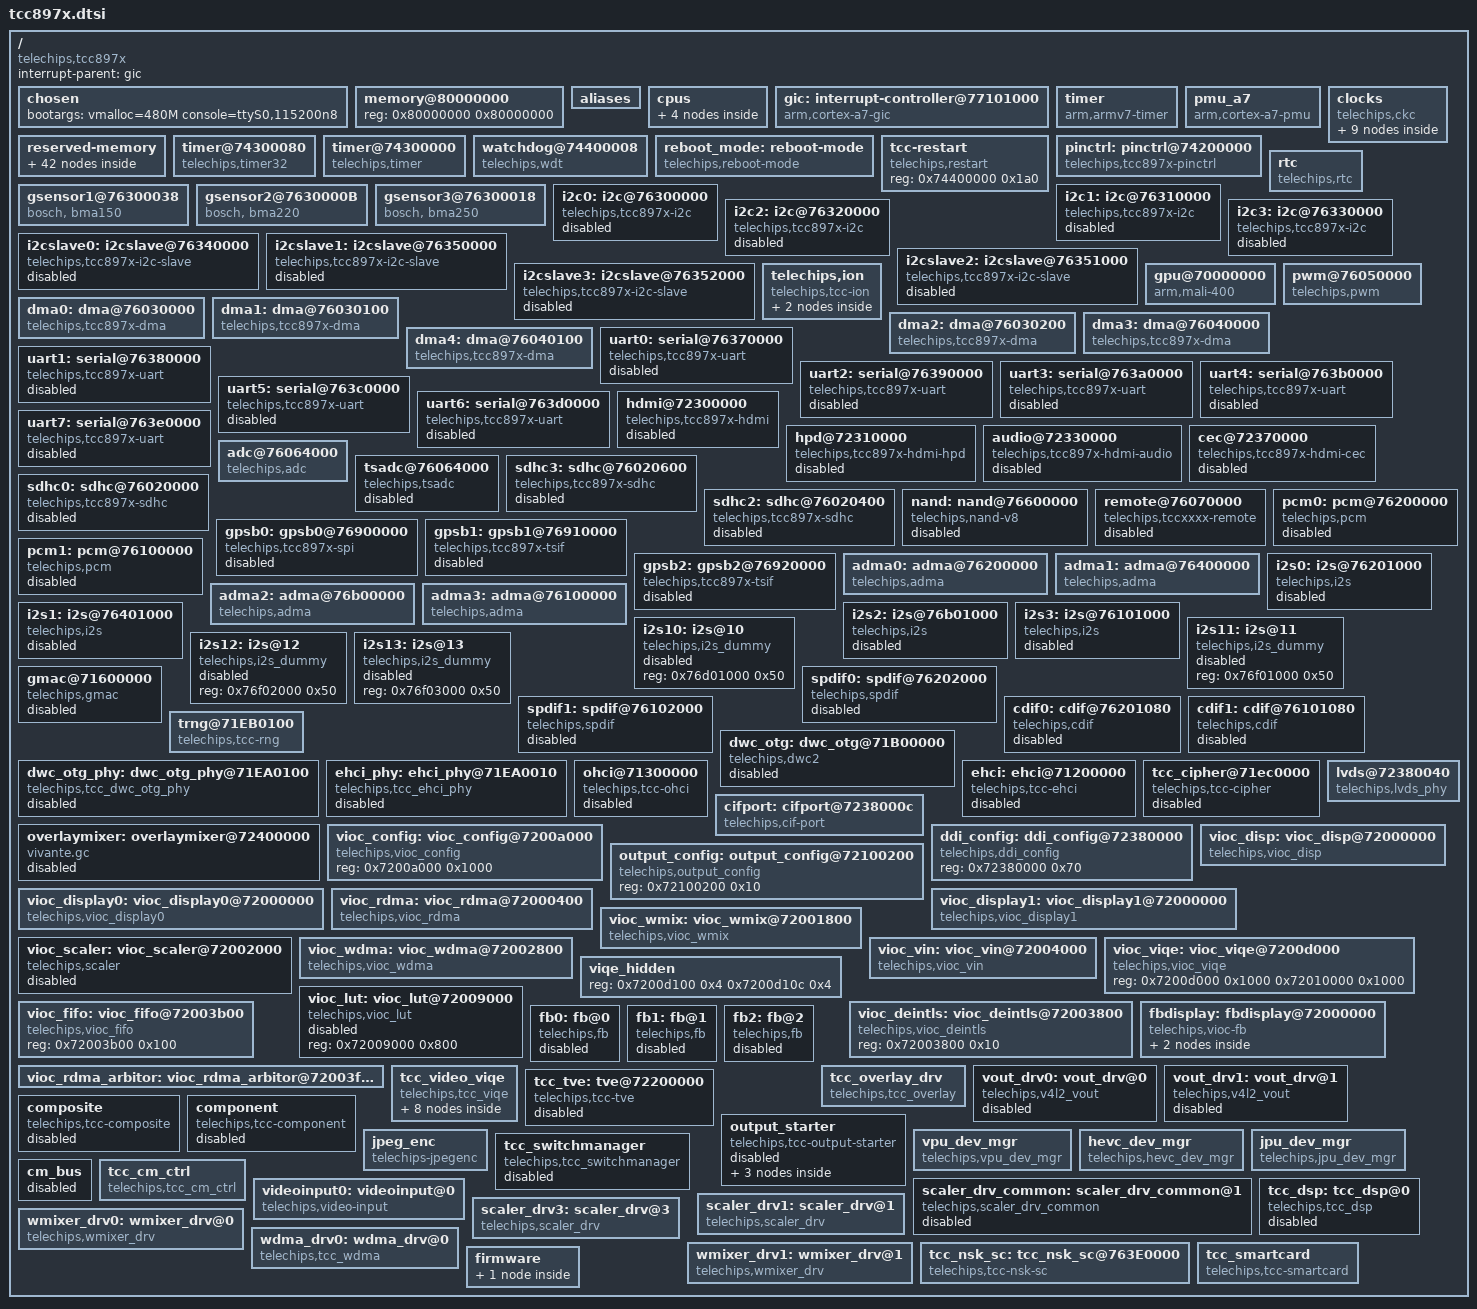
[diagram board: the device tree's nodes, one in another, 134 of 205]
// SPDX-License-Identifier: (GPL-2.0+ OR MIT)
/*
 * Device tree for Telechips TCC897x SoC
 *
 * Copyright (C) 2018 Telechips Inc.
 */

#include <dt-bindings/interrupt-controller/arm-gic.h>
#include <dt-bindings/clock/telechips,tcc897x-clks.h>
#include <dt-bindings/soc/tcc897x-pm.h>
#include <dt-bindings/display/tcc897x-vioc.h>
#include <dt-bindings/power/telechips,boot-mode.h>

#include "tcc-pmap-common.dtsi"

/ {
	compatible = "telechips,tcc897x";
	interrupt-parent = <&gic>;
	#address-cells = <1>;
	#size-cells = <1>;

	chosen {
		bootargs = "vmalloc=480M console=ttyS0,115200n8";
	};

	memory@80000000 {
		#address-cells = <1>;
		#size-cells = <1>;
		device_type = "memory";
		reg = <0x80000000 0x80000000>;
	};

	aliases {
		serial0 = &uart0;
		serial1 = &uart1;
		serial2 = &uart2;
		serial3 = &uart3;
		serial4 = &uart4;
		serial5 = &uart5;
		serial6 = &uart6;
		serial7 = &uart7;
		i2c0 = &i2c0;
		i2c1 = &i2c1;
		i2c2 = &i2c2;
		i2c3 = &i2c3;
		sdhc0 = &sdhc0;
		sdhc2 = &sdhc2;
		sdhc3 = &sdhc3;
		ehci = &ehci;
		pcm0 = &pcm0;
		pcm1 = &pcm1;
		adma0 = &adma0;
		adma1 = &adma1;
		adma2 = &adma2;
		adma3 = &adma3;
		i2s0 = &i2s0;
		i2s1 = &i2s1;
		i2s2 = &i2s2;
		i2s3 = &i2s3;
		i2s10 = &i2s10;
		i2s11 = &i2s11;
		i2s12 = &i2s12;
		i2s13 = &i2s13;
		spdif0 = &spdif0;
		spdif1 = &spdif1;
		cdif0 = &cdif0;
		cdif1 = &cdif1;
		dma0 = &dma0;
		dma1 = &dma1;
		dma2 = &dma2;
		dma3 = &dma3;
		dma4 = &dma4;
		wmixer_drv0 = &wmixer_drv0;
		wmixer_drv1 = &wmixer_drv1;
		scaler_drv1 = &scaler_drv1;
		scaler_drv3 = &scaler_drv3;
		vout_drv0 = &vout_drv0;
		vout_drv1 = &vout_drv1;
		wdma_drv0 = &wdma_drv0;
		videoinput0 = &videoinput0;
		fb0 = &fb0;
		fb1 = &fb1;
		fb2 = &fb2;
	};

	cpus {
		#address-cells = <1>;
		#size-cells = <0>;
		cpu0: cpu@0 {
			device_type = "cpu";
			compatible = "arm,cortex-a7";
			reg = <0x0>;
			clock-frequency = <1000000000>;
			operating-points = <
				/* kHz    uV */
				1000000	1100000
				 925000	1050000
				 850000	1000000
				 775000	 950000
				 700000	 900000
			>;
		};
		cpu1: cpu@1 {
			device_type = "cpu";
			compatible = "arm,cortex-a7";
			reg = <0x1>;
			clock-frequency = <1000000000>;
		};
		cpu2: cpu@2 {
			device_type = "cpu";
			compatible = "arm,cortex-a7";
			reg = <0x2>;
			clock-frequency = <1000000000>;
		};
		cpu3: cpu@3 {
			device_type = "cpu";
			compatible = "arm,cortex-a7";
			reg = <0x3>;
			clock-frequency = <1000000000>;
		};
	};

	gic:interrupt-controller@77101000 {
		compatible = "arm,cortex-a7-gic", "telechips,tcc897x-vpic";
		#interrupt-cells = <3>;
		#address-cells = <0>;
		interrupt-controller;
		reg = <0x77101000 0x1000>,
		      <0x77102000 0x1000>,
		      <0x74100000 0x260>,
		      <0x7460000c 0x8>;
	};

	timer {
		compatible = "arm,armv7-timer";
		interrupts = <GIC_PPI 13 (GIC_CPU_MASK_SIMPLE(4) | IRQ_TYPE_LEVEL_LOW)>,
		             <GIC_PPI 14 (GIC_CPU_MASK_SIMPLE(4) | IRQ_TYPE_LEVEL_LOW)>,
		             <GIC_PPI 11 (GIC_CPU_MASK_SIMPLE(4) | IRQ_TYPE_LEVEL_LOW)>,
		             <GIC_PPI 10 (GIC_CPU_MASK_SIMPLE(4) | IRQ_TYPE_LEVEL_LOW)>;
		always-on;
	};

	pmu_a7 {
		compatible = "arm,cortex-a7-pmu";
		interrupts = <GIC_SPI 64 IRQ_TYPE_LEVEL_LOW>,
		             <GIC_SPI 65 IRQ_TYPE_LEVEL_LOW>,
		             <GIC_SPI 66 IRQ_TYPE_LEVEL_LOW>,
		             <GIC_SPI 67 IRQ_TYPE_LEVEL_LOW>;
	};

	clocks {
		compatible = "telechips,ckc";
		#address-cells = <1>;
		#size-cells = <1>;
		reg = <0x74000000 0x1A8	/* ckc */
		       0x74400000 0x114	/* pmu */
		       0x73810000 0x018	/* memory bus configutaion */
		       0x72380000 0x008	/* display bus configutaion */
		       0x70010000 0x008	/* graphic bus configutaion */
		       0x76066000 0x070	/* io bus configutaion */
		       0x75100000 0x008	/* video bus configutaion */
		       0x71EA0000 0x008	/* hsio bus configutaion */
		       >;
		ranges;

		osc24m: oscillator {
			compatible = "fixed-clock";
			#clock-cells = <0>;
			clock-frequency = <24000000>;
			clock-output-names = "osc24m";
		};

		clk_pll: pll_clk {
			compatible = "telechips,clk-pll";
			#clock-cells = <1>;
			clocks = <&osc24m>;
			clock-output-names = "pll0", "pll1", "pll2", "pll_cb",
					     "pll_mb";
		};

		clk_fbus: clk@74000000 {
			compatible = "telechips,clk-fbus";
			#clock-cells = <1>;
			clock-indices =
				<FBUS_CPU0>, <FBUS_CPU1>, <FBUS_MEM>, <FBUS_DDI>,
				<FBUS_GPU>, <FBUS_IO>, <FBUS_VBUS>, <FBUS_CODA>,
				<FBUS_HSIO>, <FBUS_SMU>, <FBUS_G2D>, <FBUS_CMBUS>,
				<FBUS_HEVC_VCE>, <FBUS_HEVC_VCPU>,
				<FBUS_HEVC_BPU>;
			clock-output-names =
				"fbus_cpu0", "fbus_cpu1", "fbus_mem", "fbus_ddi",
				"fbus_gpu", "fbus_io", "fbus_vbus", "fbus_coda",
				"fbus_hsio", "fbus_smu", "fbus_g2d", "fbus_cmbus",
				"fbus_hevc_vce", "fbus_hevc_vcpu",
				"fbus_hevc_bpu";
			telechips,clock-flags =
				<0>,	/* FBUS_CPU0 */
				<0>,	/* FBUS_CPU1 */
				<(CLK_SET_RATE_GATE | CLK_IGNORE_UNUSED)>,	/* FBUS_MEM */
				<CLK_SET_RATE_GATE>,	/* FBUS_DDI */
				<0>,	/* FBUS_GPU */
				<(CLK_SET_RATE_GATE | CLK_IS_CRITICAL)>,	/* FBUS_IO */
				<CLK_SET_RATE_GATE>,	/* FBUS_VBUS */
				<CLK_SET_RATE_GATE>,	/* FBUS_CODA */
				<CLK_SET_RATE_GATE>,	/* FBUS_HSIO */
				<(CLK_SET_RATE_GATE | CLK_IGNORE_UNUSED)>,	/* FBUS_SMU */
				<CLK_SET_RATE_GATE>,	/* FBUS_G2D */
				<(CLK_SET_RATE_GATE | CLK_IGNORE_UNUSED)>,	/* FBUS_CMBUS */
				<CLK_SET_RATE_GATE>,	/* FBUS_HEVC_VCE */
				<CLK_SET_RATE_GATE>,	/* FBUS_HEVC_VCPU */
				<CLK_SET_RATE_GATE>;	/* FBUS_HEVC_BPU */
		};

		clk_peri: clk@74000080 {
			compatible = "telechips,clk-peri";
			#clock-cells = <1>;
			clock-indices =
				<PERI_TCX>, <PERI_TCT>, <PERI_TCZ>, <PERI_LCD0>,
				<PERI_LCDSI0>, <PERI_LCD1>, <PERI_LCDSI1>,
				<PERI_LCDTIMER>, <PERI_USB_OTG>,
				<PERI_GMAC_PTP>, <PERI_GMAC>, <PERI_USB_OTG_ADP>,
				<PERI_IOB_CEC>, <PERI_OUT0>, <PERI_HDMI>,
				<PERI_HDMIA>, <PERI_OUT1>, <PERI_REMOTE>,
				<PERI_SDMMC0>, <PERI_SDMMC1>, <PERI_SDMMC2>,
				<PERI_SDMMC3>, <PERI_ADAI3>, <PERI_ADAM3>,
				<PERI_SPDIF3>, <PERI_ADAI0>, <PERI_ADAM0>,
				<PERI_SPDIF0>, <PERI_PDM>, <PERI_CMBUS_CNT>,
				<PERI_ADC>, <PERI_I2C0>, <PERI_I2C1>, <PERI_I2C2>,
				<PERI_I2C3>, <PERI_UART0>, <PERI_UART1>,
				<PERI_UART2>, <PERI_UART3>, <PERI_UART4>,
				<PERI_UART5>, <PERI_UART6>, <PERI_UART7>,
				<PERI_GPSB0>, <PERI_GPSB1>, <PERI_GPSB2>,
				<PERI_I2C6>, <PERI_I2C7>, <PERI_OUT2>, <PERI_OUT3>,
				<PERI_OUT4>, <PERI_OUT5>, <PERI_TSTX0>,
				<PERI_CMBUS_TSIF0>, <PERI_CMBUS_TSIF1>,
				<PERI_CMBUS_TSIF2>, <PERI_CMBUS_TSIF3>, <PERI_I2C4>,
				<PERI_I2C5>, <PERI_HDMI_PCLK>, <PERI_ADAI1>,
				<PERI_ADAM1>, <PERI_SPDIF1>, <PERI_ADAI2>,
				<PERI_ADAM2>, <PERI_SPDIF2>;
			clock-output-names =
				"peri_tcx", "peri_tct", "peri_tcz", "peri_lcd0",
				"peri_lcdsi0", "peri_lcd1", "peri_lcdsi1",
				"peri_lcdtimer", "peri_usb_otg",
				"peri_gmac_ptp", "peri_gmac", "peri_usb_otg_adp",
				"peri_iob_cec", "peri_out0", "peri_hdmi",
				"peri_hdmia", "peri_out1", "peri_remote",
				"peri_sdmmc0", "peri_sdmmc1", "peri_sdmmc2",
				"peri_sdmmc3", "peri_adai3", "peri_adam3",
				"peri_spdif3", "peri_adai0", "peri_adam0",
				"peri_spdif0", "peri_pdm", "peri_cmbus_cnt",
				"peri_adc", "peri_i2c0", "peri_i2c1", "peri_i2c2",
				"peri_i2c3", "peri_uart0", "peri_uart1",
				"peri_uart2", "peri_uart3", "peri_uart4",
				"peri_uart5", "peri_uart6", "peri_uart7",
				"peri_gpsb0", "peri_gpsb1", "peri_gpsb2",
				"peri_i2c6", "peri_i2c7", "peri_out2", "peri_out3",
				"peri_out4", "peri_out5", "peri_tstx0",
				"peri_cmbus_tsif0", "peri_cmbus_tsif1",
				"peri_cmbus_tsif2", "peri_cmbus_tsif3", "peri_i2c4",
				"peri_i2c5", "peri_hdmi_pclk", "peri_adai1",
				"peri_adam1", "peri_spdif1", "peri_adai2",
				"peri_adam2", "peri_spdif2";
			telechips,clock-flags =
				<0>,	/* PERI_TCX */
				<0>,	/* PERI_TCT */
				<CLK_IGNORE_UNUSED>,	/* PERI_TCZ */
				<0>,	/* PERI_LCD0 */
				<0>,	/* PERI_LCDSI0 */
				<0>,	/* PERI_LCD1 */
				<0>,	/* PERI_LCDSI1 */
				<0>,	/* PERI_LCDTIMER */
				<0>,	/* PERI_USB_OTG */
				<0>,	/* PERI_GMAC_PTP */
				<0>,	/* PERI_GMAC */
				<0>,	/* PERI_USB_OTG_ADP */
				<0>,	/* PERI_IOB_CEC */
				<0>,	/* PERI_OUT0 */
				<0>,	/* PERI_HDMI */
				<0>,	/* PERI_HDMIA */
				<0>,	/* PERI_OUT1 */
				<0>,	/* PERI_REMOTE */
				<0>,	/* PERI_SDMMC0 */
				<0>,	/* PERI_SDMMC1 */
				<0>,	/* PERI_SDMMC2 */
				<0>,	/* PERI_SDMMC3 */
				<0>,	/* PERI_ADAI3 */
				<0>,	/* PERI_ADAM3 */
				<0>,	/* PERI_SPDIF3 */
				<0>,	/* PERI_ADAI0 */
				<0>,	/* PERI_ADAM0 */
				<0>,	/* PERI_SPDIF0 */
				<0>,	/* PERI_PDM */
				<CLK_IGNORE_UNUSED>,	/* PERI_CMBUS_CNT */
				<0>,	/* PERI_ADC */
				<0>,	/* PERI_I2C0 */
				<0>,	/* PERI_I2C1 */
				<0>,	/* PERI_I2C2 */
				<0>,	/* PERI_I2C3 */
				<0>,	/* PERI_UART0 */
				<0>,	/* PERI_UART1 */
				<0>,	/* PERI_UART2 */
				<0>,	/* PERI_UART3 */
				<0>,	/* PERI_UART4 */
				<0>,	/* PERI_UART5 */
				<0>,	/* PERI_UART6 */
				<0>,	/* PERI_UART7 */
				<0>,	/* PERI_GPSB0 */
				<0>,	/* PERI_GPSB1 */
				<0>,	/* PERI_GPSB2 */
				<0>,	/* PERI_I2C6 */
				<0>,	/* PERI_I2C7 */
				<0>,	/* PERI_OUT2 */
				<0>,	/* PERI_OUT3 */
				<0>,	/* PERI_OUT4 */
				<0>,	/* PERI_OUT5 */
				<0>,	/* PERI_TSTX0 */
				<0>,	/* PERI_CMBUS_TSIF0 */
				<0>,	/* PERI_CMBUS_TSIF1 */
				<0>,	/* PERI_CMBUS_TSIF2 */
				<0>,	/* PERI_CMBUS_TSIF3 */
				<0>,	/* PERI_I2C4 */
				<0>,	/* PERI_I2C5 */
				<0>,	/* PERI_HDMI_PCLK */
				<CLK_IGNORE_UNUSED>,	/* PERI_ADAI1 */
				<CLK_IGNORE_UNUSED>,	/* PERI_ADAM1 */
				<0>,	/* PERI_SPDIF1 */
				<0>,	/* PERI_ADAI2 */
				<0>,	/* PERI_ADAM2 */
				<0>;	/* PERI_SPDIF2 */
		};

		clk_isoip_top: clk@7440009c {
			compatible = "telechips,clk-isoip_top";
			#clock-cells = <1>;
			clock-indices =
				<ISOIP_TOP_OTP>, <ISOIP_TOP_RTC>,
				<ISOIP_TOP_PLL>, <ISOIP_TOP_ECID>,
				<ISOIP_TOP_HDMI>, <ISOIP_TOP_VDAC_3CH>,
				<ISOIP_TOP_VDAC_1CH>, <ISOIP_TOP_TSADC>,
				<ISOIP_TOP_USB2P>, <ISOIP_TOP_USBOTG>,
				<ISOIP_TOP_LVDS>;
			clock-output-names =
				"isoip_top_otp", "isoip_top_rtc",
				"isoip_top_pll", "isoip_top_ecid",
				"isoip_top_hdmi", "isoip_top_vdac_3ch",
				"isoip_top_vdac_1ch", "isoip_top_tsadc",
				"isoip_top_usb2p", "isoip_top_usbotg",
				"isoip_top_lvds";
			telechips,clock-flags =
				<(CLK_SET_RATE_GATE | CLK_IGNORE_UNUSED)>,	/* ISOIP_TOP_OTP */
				<(CLK_SET_RATE_GATE | CLK_IGNORE_UNUSED)>,	/* ISOIP_TOP_RTC */
				<(CLK_SET_RATE_GATE | CLK_IGNORE_UNUSED)>,	/* ISOIP_TOP_PLL */
				<CLK_SET_RATE_GATE>,	/* ISOIP_TOP_ECID */
				<CLK_SET_RATE_GATE>,	/* ISOIP_TOP_HDMI */
				<CLK_SET_RATE_GATE>,	/* ISOIP_TOP_VDAC_3CH */
				<CLK_SET_RATE_GATE>,	/* ISOIP_TOP_VDAC_1CH */
				<CLK_SET_RATE_GATE>,	/* ISOIP_TOP_TSADC */
				<CLK_SET_RATE_GATE>,	/* ISOIP_TOP_USB2P */
				<CLK_SET_RATE_GATE>,	/* ISOIP_TOP_USBOTG */
				<CLK_SET_RATE_GATE>;	/* ISOIP_TOP_LVDS */
		};

		clk_ddi: clk@72380000 {
			compatible = "telechips,clk-ddibus";
			#clock-cells = <1>;
			clock-indices =
				<DDIBUS_VIOC>, <DDIBUS_NTSCPAL>, <DDIBUS_HDMI>,
				<DDIBUS_G2D>;
			clock-output-names =
				"ddibus_vioc", "ddibus_ntscpal", "ddibus_hdmi",
				"ddibus_g2d";
			telechips,clock-flags =
				<CLK_IGNORE_UNUSED>,	/* DDIBUS_VIOC */
				<CLK_IGNORE_UNUSED>,	/* DDIBUS_NTSCPAL */
				<CLK_IGNORE_UNUSED>,	/* DDIBUS_HDMI */
				<CLK_IGNORE_UNUSED>;	/* DDIBUS_G2D */
		};

		clk_io: clk@76066000 {
			compatible = "telechips,clk-iobus";
			#clock-cells = <1>;
			clock-indices =
				<IOBUS_SDMMC0>, <IOBUS_SDMMC2>, <IOBUS_SDMMC3>,
				<IOBUS_SDMMC>, <IOBUS_DMA0>, <IOBUS_DMA1>,
				<IOBUS_DMA2>, <IOBUS_DMA>, <IOBUS_PWM>, <IOBUS_SMC>,
				<IOBUS_I2C_S2>, <IOBUS_RTC>, <IOBUS_REMOCON>,
				<IOBUS_TSADC>, <IOBUS_EDICFG>, <IOBUS_EDI>,
				<IOBUS_PROT>, <IOBUS_ADMA0>, <IOBUS_DAI0>,
				<IOBUS_SPDIF0>, <IOBUS_AUDIO0>, <IOBUS_ADMA3>,
				<IOBUS_DAI3>, <IOBUS_SPDIF3>, <IOBUS_AUDIO3>,
				<IOBUS_I2C_M0>, <IOBUS_I2C_M1>, <IOBUS_I2C_M2>,
				<IOBUS_I2C_M3>, <IOBUS_I2C_S0>, <IOBUS_I2C_S1>,
				<IOBUS_I2C>, <IOBUS_UART0>, <IOBUS_UART1>,
				<IOBUS_UART2>, <IOBUS_UART3>, <IOBUS_UART4>,
				<IOBUS_UART5>, <IOBUS_UART6>, <IOBUS_UART7>,
				<IOBUS_UART>, <IOBUS_NFC>, <IOBUS_TS0>, <IOBUS_GPSB0>,
				<IOBUS_GPSB1>, <IOBUS_GPSB2>, <IOBUS_GPSB>,
				<IOBUS_CEC>, <IOBUS_I2C_S3>, <IOBUS_I2C_M4>,
				<IOBUS_I2C_M5>, <IOBUS_I2C_M6>, <IOBUS_I2C_M7>,
				<IOBUS_DMAC0>, <IOBUS_DMAC1>, <IOBUS_DMAC2>,
				<IOBUS_DMAC>, <IOBUS_ADMA1>, <IOBUS_DAI1>,
				<IOBUS_SPDIF1>, <IOBUS_AUDIO1>, <IOBUS_ADMA2>,
				<IOBUS_DAI2>, <IOBUS_SPDIF2>, <IOBUS_AUDIO2>;
			clock-output-names =
				"iobus_sdmmc0", "iobus_sdmmc2", "iobus_sdmmc3",
				"iobus_sdmmc", "iobus_dma0", "iobus_dma1",
				"iobus_dma2", "iobus_dma", "iobus_pwm", "iobus_smc",
				"iobus_i2c_s2", "iobus_rtc", "iobus_remocon",
				"iobus_tsadc", "iobus_edicfg", "iobus_edi",
				"iobus_prot", "iobus_adma0", "iobus_dai0",
				"iobus_spdif0", "iobus_audio0", "iobus_adma3",
				"iobus_dai3", "iobus_spdif3", "iobus_audio3",
				"iobus_i2c_m0", "iobus_i2c_m1", "iobus_i2c_m2",
				"iobus_i2c_m3", "iobus_i2c_s0", "iobus_i2c_s1",
				"iobus_i2c", "iobus_uart0", "iobus_uart1",
				"iobus_uart2", "iobus_uart3", "iobus_uart4",
				"iobus_uart5", "iobus_uart6", "iobus_uart7",
				"iobus_uart", "iobus_nfc", "iobus_ts0", "iobus_gpsb0",
				"iobus_gpsb1", "iobus_gpsb2", "iobus_gpsb",
				"iobus_cec", "iobus_i2c_s3", "iobus_i2c_m4",
				"iobus_i2c_m5", "iobus_i2c_m6", "iobus_i2c_m7",
				"iobus_dmac0", "iobus_dmac1", "iobus_dmac2",
				"iobus_dmac", "iobus_adma1", "iobus_dai1",
				"iobus_spdif1", "iobus_audio1", "iobus_adma2",
				"iobus_dai2", "iobus_spdif2", "iobus_audio2";
			telechips,clock-flags =
				<CLK_IGNORE_UNUSED>,	/* IOBUS_SDMMC0 */
				<CLK_IGNORE_UNUSED>,	/* IOBUS_SDMMC2 */
				<CLK_IGNORE_UNUSED>,	/* IOBUS_SDMMC3 */
				<CLK_IGNORE_UNUSED>,	/* IOBUS_SDMMC */
				<CLK_IGNORE_UNUSED>,	/* IOBUS_DMA0 */
				<CLK_IGNORE_UNUSED>,	/* IOBUS_DMA1 */
				<CLK_IGNORE_UNUSED>,	/* IOBUS_DMA2 */
				<CLK_IGNORE_UNUSED>,	/* IOBUS_DMA */
				<CLK_IGNORE_UNUSED>,	/* IOBUS_PWM */
				<CLK_IGNORE_UNUSED>,	/* IOBUS_SMC */
				<CLK_IGNORE_UNUSED>,	/* IOBUS_I2C_S2 */
				<CLK_IGNORE_UNUSED>,	/* IOBUS_RTC */
				<CLK_IGNORE_UNUSED>,	/* IOBUS_REMOCON */
				<CLK_IGNORE_UNUSED>,	/* IOBUS_TSADC */
				<CLK_IGNORE_UNUSED>,	/* IOBUS_EDICFG */
				<CLK_IGNORE_UNUSED>,	/* IOBUS_EDI */
				<CLK_IGNORE_UNUSED>,	/* IOBUS_PROT */
				<CLK_IGNORE_UNUSED>,	/* IOBUS_ADMA0 */
				<CLK_IGNORE_UNUSED>,	/* IOBUS_DAI0 */
				<CLK_IGNORE_UNUSED>,	/* IOBUS_SPDIF0 */
				<CLK_IGNORE_UNUSED>,	/* IOBUS_AUDIO0 */
				<CLK_IGNORE_UNUSED>,	/* IOBUS_ADMA3 */
				<CLK_IGNORE_UNUSED>,	/* IOBUS_DAI3 */
				<CLK_IGNORE_UNUSED>,	/* IOBUS_SPDIF3 */
				<CLK_IGNORE_UNUSED>,	/* IOBUS_AUDIO3 */
				<CLK_IGNORE_UNUSED>,	/* IOBUS_I2C_M0 */
				<CLK_IGNORE_UNUSED>,	/* IOBUS_I2C_M1 */
				<CLK_IGNORE_UNUSED>,	/* IOBUS_I2C_M2 */
				<CLK_IGNORE_UNUSED>,	/* IOBUS_I2C_M3 */
				<CLK_IGNORE_UNUSED>,	/* IOBUS_I2C_S0 */
				<CLK_IGNORE_UNUSED>,	/* IOBUS_I2C_S1 */
				<CLK_IGNORE_UNUSED>,	/* IOBUS_I2C */
				<CLK_IGNORE_UNUSED>,	/* IOBUS_UART0 */
				<CLK_IGNORE_UNUSED>,	/* IOBUS_UART1 */
				<CLK_IGNORE_UNUSED>,	/* IOBUS_UART2 */
				<CLK_IGNORE_UNUSED>,	/* IOBUS_UART3 */
				<CLK_IGNORE_UNUSED>,	/* IOBUS_UART4 */
				<CLK_IGNORE_UNUSED>,	/* IOBUS_UART5 */
				<CLK_IGNORE_UNUSED>,	/* IOBUS_UART6 */
				<CLK_IGNORE_UNUSED>,	/* IOBUS_UART7 */
				<CLK_IGNORE_UNUSED>,	/* IOBUS_UART */
				<CLK_IGNORE_UNUSED>,	/* IOBUS_NFC */
				<CLK_IGNORE_UNUSED>,	/* IOBUS_TS0 */
				<CLK_IGNORE_UNUSED>,	/* IOBUS_GPSB0 */
				<CLK_IGNORE_UNUSED>,	/* IOBUS_GPSB1 */
				<CLK_IGNORE_UNUSED>,	/* IOBUS_GPSB2 */
				<CLK_IGNORE_UNUSED>,	/* IOBUS_GPSB */
				<CLK_IGNORE_UNUSED>,	/* IOBUS_CEC */
				<CLK_IGNORE_UNUSED>,	/* IOBUS_I2C_S3 */
				<CLK_IGNORE_UNUSED>,	/* IOBUS_I2C_M4 */
				<CLK_IGNORE_UNUSED>,	/* IOBUS_I2C_M5 */
				<CLK_IGNORE_UNUSED>,	/* IOBUS_I2C_M6 */
				<CLK_IGNORE_UNUSED>,	/* IOBUS_I2C_M7 */
				<CLK_IGNORE_UNUSED>,	/* IOBUS_DMAC0 */
				<CLK_IGNORE_UNUSED>,	/* IOBUS_DMAC1 */
				<CLK_IGNORE_UNUSED>,	/* IOBUS_DMAC2 */
				<CLK_IGNORE_UNUSED>,	/* IOBUS_DMAC */
				<CLK_IGNORE_UNUSED>,	/* IOBUS_ADMA1 */
				<CLK_IGNORE_UNUSED>,	/* IOBUS_DAI1 */
				<CLK_IGNORE_UNUSED>,	/* IOBUS_SPDIF1 */
				<CLK_IGNORE_UNUSED>,	/* IOBUS_AUDIO1 */
				<CLK_IGNORE_UNUSED>,	/* IOBUS_ADMA2 */
				<CLK_IGNORE_UNUSED>,	/* IOBUS_DAI2 */
				<CLK_IGNORE_UNUSED>,	/* IOBUS_SPDIF2 */
				<CLK_IGNORE_UNUSED>;	/* IOBUS_AUDIO2 */
		};

		clk_vpu: clk@75100000 {
			compatible = "telechips,clk-vpubus";
			#clock-cells = <1>;
			clock-indices =
				<VIDEOBUS_JENC>, <VIDEOBUS_COD>,
				<VIDEOBUS_VBUS>, <VIDEOBUS_HEVC>;
			clock-output-names =
				"videobus_jenc", "videobus_cod",
				"videobus_vbus", "videobus_hevc";
			telechips,clock-flags =
				<CLK_IGNORE_UNUSED>,	/* VIDEOBUS_JENC */
				<CLK_IGNORE_UNUSED>,	/* VIDEOBUS_COD */
				<CLK_IGNORE_UNUSED>,	/* VIDEOBUS_VBUS */
				<CLK_IGNORE_UNUSED>;	/* VIDEOBUS_HEVC */
		};

		clk_hsio: clk@71ea0000 {
			compatible = "telechips,clk-hsiobus";
			#clock-cells = <1>;
			clock-indices =
				<HSIOBUS_USBOTG>, <HSIOBUS_GMAC>,
				<HSIOBUS_USB20H>, <HSIOBUS_CIPHER>, <HSIOBUS_TRNG>;
			clock-output-names =
				"hsiobus_usbotg", "hsiobus_gmac",
				"hsiobus_usb20h", "hsiobus_cipher", "hsiobus_trng";
			telechips,clock-flags =
				<CLK_IGNORE_UNUSED>,	/* HSIOBUS_USBOTG */
				<CLK_IGNORE_UNUSED>,	/* HSIOBUS_GMAC */
				<CLK_IGNORE_UNUSED>,	/* HSIOBUS_USB20H */
				<CLK_IGNORE_UNUSED>,	/* HSIOBUS_CIPHER */
				<CLK_IGNORE_UNUSED>;	/* HSIOBUS_TRNG */
		};
	};

	reserved-memory {
		#address-cells = <1>;
		#size-cells = <1>;
		ranges;

		/*-----------------------------------------------------------
		 * Secure Area 1 (CPU R/W, VPU X, GPU R/W, VIOC R)
		 *-----------------------------------------------------------
		 */
		pmap_fb_video: fb_video {
			compatible = "telechips,pmap";
			telechips,pmap-name = "fb_video";
			alloc-ranges = <SECURE_AREA_1_BASE SECURE_AREA_1_SIZE>;
			size = <PMAP_SIZE_FB_VIDEO>;
			telechips,pmap-secured = <1>;
			no-map;
		};

		pmap_fb1_video: fb1_video {
			compatible = "telechips,pmap";
			telechips,pmap-name = "fb1_video";
			alloc-ranges = <SECURE_AREA_1_BASE SECURE_AREA_1_SIZE>;
			size = <PMAP_SIZE_FB1_VIDEO>;
			telechips,pmap-secured = <1>;
			no-map;
		};

		pmap_fb2_video: fb2_video {
			compatible = "telechips,pmap";
			telechips,pmap-name = "fb2_video";
			alloc-ranges = <SECURE_AREA_1_BASE SECURE_AREA_1_SIZE>;
			size = <PMAP_SIZE_FB2_VIDEO>;
			telechips,pmap-secured = <1>;
			no-map;
		};

		/*-----------------------------------------------------------
		 * Secure Area 2 (CPU X, VPU X, GPU X, VIOC R/W)
		 *-----------------------------------------------------------
		 */
		pmap_overlay: overlay {
			compatible = "telechips,pmap";
			telechips,pmap-name = "overlay";
			alloc-ranges = <SECURE_AREA_2_BASE SECURE_AREA_2_SIZE>;
			size = <PMAP_SIZE_OVERLAY>; // Max-Displayed-Output(w*h*2) * 3
			telechips,pmap-secured = <2>;
			no-map;
		};

		pmap_overlay1: overlay1 {
			compatible = "telechips,pmap";
			telechips,pmap-name = "overlay1";
			alloc-ranges = <SECURE_AREA_2_BASE SECURE_AREA_2_SIZE>;
			size = <PMAP_SIZE_OVERLAY1>; // Max-Displayed-Output(w*h*2) * 3
			telechips,pmap-secured = <2>;
			no-map;
		};

		pmap_overlay_rot: overlay_rot {
			compatible = "telechips,pmap";
			telechips,pmap-name = "overlay_rot";
			alloc-ranges = <SECURE_AREA_2_BASE SECURE_AREA_2_SIZE>;
			size = <PMAP_SIZE_OVERLAY_ROT>; // Max-Displayed-Output(w*h*2) for device-rotation.
			telechips,pmap-secured = <2>;
			no-map;
		};

		pmap_viqe0: viqe0 {
			compatible = "telechips,pmap";
			telechips,pmap-name = "viqe";
			alloc-ranges = <SECURE_AREA_2_BASE SECURE_AREA_2_SIZE>;
			size = <PMAP_SIZE_VIQE0>;
			telechips,pmap-secured = <2>;
			no-map;
		};

		pmap_viqe1: viqe1 {
			compatible = "telechips,pmap";
			telechips,pmap-name = "viqe1";
			alloc-ranges = <SECURE_AREA_2_BASE SECURE_AREA_2_SIZE>;
			size = <PMAP_SIZE_VIQE1>;
			telechips,pmap-secured = <2>;
			no-map;
		};

		pmap_output_attach: output_attach {
			compatible = "telechips,pmap";
			telechips,pmap-name = "output_attach";
			alloc-ranges = <SECURE_AREA_2_BASE SECURE_AREA_2_SIZE>;
			size = <PMAP_SIZE_OUTPUT_ATTACH>;
			telechips,pmap-secured = <2>;
			no-map;
		};

		pmap_v4l2_vout0: v4l2_vout0 {
			compatible = "telechips,pmap";
			telechips,pmap-name = "v4l2_vout0";
			alloc-ranges = <SECURE_AREA_2_BASE SECURE_AREA_2_SIZE>;
			size = <PMAP_SIZE_V4L2_VOUT0>;
			telechips,pmap-secured = <2>;
			no-map;
		};

		pmap_v4l2_vout1: v4l2_vout1 {
			compatible = "telechips,pmap";
			telechips,pmap-name = "v4l2_vout1";
			alloc-ranges = <SECURE_AREA_2_BASE SECURE_AREA_2_SIZE>;
			size = <PMAP_SIZE_V4L2_VOUT1>;
			telechips,pmap-secured = <2>;
			no-map;
		};

		pmap_video_dual: video_dual {
			compatible = "telechips,pmap";
			telechips,pmap-name = "video_dual";
			alloc-ranges = <SECURE_AREA_2_BASE SECURE_AREA_2_SIZE>;
			size = <PMAP_SIZE_VIDEO_DUAL>;
			telechips,pmap-secured = <2>;
			no-map;
		};

		pmap_fb_wmixer: fb_wmixer {
			compatible = "telechips,pmap";
			telechips,pmap-name = "fb_wmixer";
			alloc-ranges = <SECURE_AREA_2_BASE SECURE_AREA_2_SIZE>;
			size = <PMAP_SIZE_FB_WMIXER>; // Max-Video-Resolution(w*h*2)
			telechips,pmap-secured = <2>;
			no-map;
		};

		/*-----------------------------------------------------------
		 * Secure Area 3 (CPU X, VPU R/W, GPU X, VIOC R)
		 *-----------------------------------------------------------
		 */

		pmap_secure_inbuf: secure_inbuf {
			compatible = "telechips,pmap";
			telechips,pmap-name = "secure_inbuf";
			alloc-ranges = <SECURE_AREA_3_BASE SECURE_AREA_3_SIZE>;
			size = <PMAP_SIZE_SECURE_INBUF>;
			telechips,pmap-secured = <3>;
			no-map;
		};

		pmap_video_ext: video_ext {
			compatible = "telechips,pmap";
			telechips,pmap-name = "video_ext";
			alloc-ranges = <SECURE_AREA_3_BASE SECURE_AREA_3_SIZE>;
			size = <PMAP_SIZE_VIDEO_EXT>;
			telechips,pmap-secured = <3>;
			no-map;
		};

		pmap_video_ext2: video_ext2 {
			compatible = "telechips,pmap";
			telechips,pmap-name = "video_ext2";
			alloc-ranges = <SECURE_AREA_3_BASE SECURE_AREA_3_SIZE>;
			size = <PMAP_SIZE_VIDEO_EXT2>;
			telechips,pmap-secured = <3>;
			no-map;
		};

		pmap_video: video {
			compatible = "telechips,pmap";
			telechips,pmap-name = "video";
			alloc-ranges = <SECURE_AREA_3_BASE SECURE_AREA_3_SIZE>;
			size = <PMAP_SIZE_VIDEO>;
			telechips,pmap-secured = <3>;
			no-map;
		};

		pmap_video_sw: video_sw {
			compatible = "telechips,pmap";
			telechips,pmap-name = "video_sw";
			alloc-ranges = <RESERVED_MEM_BASE RESERVED_MEM_SIZE>;
			size = <PMAP_SIZE_VIDEO_SW_EXTRA>;
			no-map;
		};

		/*-----------------------------------------------------------
		 * Secure Area 4 (CPU X, VPU X, GPU R/W, VIOC R/W)
		 *-----------------------------------------------------------
		 */
		pmap_ump_reserved: ump_reserved {
			compatible = "telechips,pmap";
			telechips,pmap-name = "ump_reserved";
			alloc-ranges = <SECURE_AREA_4_BASE SECURE_AREA_4_SIZE>;
			size = <PMAP_SIZE_UMP_RESERVED>; // Max-Video-Resolution(Aligned_256KB(w*h*3/2)) * 12 + 1MB
			telechips,pmap-secured = <4>;
		};

                pmap_ion_carveout_cam: ion_carveout_cam {
                        compatible = "telechips,pmap";
                        telechips,pmap-name = "ion_carveout_cam";
                        alloc-ranges = <SECURE_AREA_4_BASE SECURE_AREA_4_SIZE>;
                        size = <PMAP_SIZE_ION_CARVEOUT_CAM>; // 12MB
                        telechips,pmap-secured = <4>;
                };

		/*-----------------------------------------------------------
		 * Shared Memory with pmap_viqe
		 *-----------------------------------------------------------
		 */
		pmap_jpeg_header: jpeg_header {
			compatible = "telechips,pmap";
			telechips,pmap-name = "jpeg_header";
			alloc-ranges = <RESERVED_MEM_BASE RESERVED_MEM_SIZE>;
			telechips,pmap-shared = <&pmap_viqe0>;
			telechips,pmap-shared-size = <PMAP_SIZE_JPEG_HEADER>;
			telechips,pmap-offset = <0x0>;
			size = <0x0>;
			no-map;
		};

		pmap_jpeg_stream: jpeg_stream {
			compatible = "telechips,pmap";
			telechips,pmap-name = "jpeg_stream";
			alloc-ranges = <RESERVED_MEM_BASE RESERVED_MEM_SIZE>;
			telechips,pmap-shared = <&pmap_jpeg_header>;
			telechips,pmap-shared-size = <PMAP_SIZE_JPEG_STREAM>;
			telechips,pmap-offset = <PMAP_SIZE_JPEG_HEADER>;
			size = <0x0>;
			no-map;
		};

		pmap_jpeg_raw: jpeg_raw {
			compatible = "telechips,pmap";
			telechips,pmap-name = "jpeg_raw";
			alloc-ranges = <RESERVED_MEM_BASE RESERVED_MEM_SIZE>;
			telechips,pmap-shared = <&pmap_jpeg_stream>;
			telechips,pmap-shared-size = <PMAP_SIZE_JPEG_RAW>;
			telechips,pmap-offset = <PMAP_SIZE_JPEG_STREAM>;
			size = <0x0>;
			no-map;
		};

		/*-----------------------------------------------------------
		 * Early/RearCamera Area
		 *-----------------------------------------------------------
		 */
		rearcamera_viqe: rearcamera_viqe {
			compatible = "telechips,pmap";
			telechips,pmap-name = "rearcamera_viqe";
			alloc-ranges = <EARLY_REARCAM_BASE EARLY_REARCAM_SIZE>;
			size = <PMAP_REARCAMERA_VIQE_SIZE>;
			no-map;
		};

		rearcamera: rearcamera {
			compatible = "telechips,pmap";
			telechips,pmap-name = "rearcamera";
			alloc-ranges = <EARLY_REARCAM_BASE EARLY_REARCAM_SIZE>;
			size = <PMAP_REARCAMERA_SIZE>;
			no-map;
		};

		parking_gui: parking_gui {
			compatible = "telechips,pmap";
			telechips,pmap-name = "parking_gui";
			alloc-ranges = <EARLY_REARCAM_BASE EARLY_REARCAM_SIZE>;
			size = <PMAP_PARKING_GUI_SIZE>;
			no-map;
		};

		/*-----------------------------------------------------------
		 * Default Reserved Memory
		 *-----------------------------------------------------------
		 */
		pmap_ump_reserved_sw: ump_reserved_sw {
			compatible = "telechips,pmap";
			telechips,pmap-name = "ump_reserved_sw";
			alloc-ranges = <RESERVED_MEM_BASE RESERVED_MEM_SIZE>;
			size = <PMAP_SIZE_UMP_RESERVED_SW>; // 4KB * 12
			no-map;
		};

		pmap_video_sbackup: video_sbackup {
			compatible = "telechips,pmap";
			telechips,pmap-name = "video_sbackup";
			alloc-ranges = <RESERVED_MEM_BASE RESERVED_MEM_SIZE>;
			size = <PMAP_SIZE_VIDEO_SBACKUP>;  // 0x200000 for 1080p, 0x600000 for 2160p
			telechips,pmap-secured;
			no-map;
		};

		pmap_pmem: pmem {
			compatible = "telechips,pmap";
			telechips,pmap-name = "pmem";
			alloc-ranges = <RESERVED_MEM_BASE RESERVED_MEM_SIZE>;
			size = <PMAP_SIZE_PMEM>;
			no-map;
		};

		pmap_video_thumb: video_thumb {
			compatible = "telechips,pmap";
			telechips,pmap-name = "video_thumb";
			alloc-ranges = <RESERVED_MEM_BASE RESERVED_MEM_SIZE>;
			size = <PMAP_SIZE_VIDEO_THUMB>; //0x600000 for 1080p video, 0x1A00000 for 2160p
			no-map;
		};

		pmap_ext_camera: ext_camera {
			compatible = "telechips,pmap";
			telechips,pmap-name = "ext_camera";
			alloc-ranges = <RESERVED_MEM_BASE RESERVED_MEM_SIZE>;
			size = <PMAP_SIZE_EXT_CAMERA>;
			no-map;
		};

		pmap_nand_mem: nand_mem {
			compatible = "telechips,pmap";
			telechips,pmap-name = "nand_mem";
			alloc-ranges = <RESERVED_MEM_BASE RESERVED_MEM_SIZE>;
			size = <PMAP_SIZE_NAND_MEM>;
			no-map;
		};

		pmap_tsif: tsif {
			compatible = "telechips,pmap";
			telechips,pmap-name = "tsif";
			alloc-ranges = <RESERVED_MEM_BASE RESERVED_MEM_SIZE>;
			size = <PMAP_SIZE_TSIF>;
			no-map;
		};

		/*
		pmap_jpg_enc_dxb: jpg_enc_dxb {
			telechips,pmap-name = "jpg_enc_dxb";
			alloc-ranges = <RESERVED_MEM_BASE RESERVED_MEM_SIZE>;
			size = <PMAP_SIZE_JPG_ENC_DXB>;
			no-map;
		};

		pmap_jpg_raw_dxb: jpg_raw_dxb {
			telechips,pmap-name = "jpg_raw_dxb";
			alloc-ranges = <RESERVED_MEM_BASE RESERVED_MEM_SIZE>;
			size = <PMAP_SIZE_JPG_RAW_DXB>;
			no-map;
		};
		*/

		pmap_v4l2_subtitle: v4l2_subtitle {
			compatible = "telechips,pmap";
			telechips,pmap-name = "v4l2_subtitle";
			alloc-ranges = <RESERVED_MEM_BASE RESERVED_MEM_SIZE>;
			size = <PMAP_SIZE_V4L2_SUBTITLE>;
			no-map;
		};

		pmap_prot_tztee: prot_tztee {
			compatible = "telechips,pmap";
			telechips,pmap-name = "prot_tztee";
			alloc-ranges = <RESERVED_MEM_BASE RESERVED_MEM_SIZE>;
			/* Calculate start address based on 0x30000000.
			 * Base address will be (0x30000000 - prot_tztee_size).
			 */
			size = <0x0>;
			no-map;
		};

		reserved_ramoops: ramoops {
			compatible = "telechips,pmap";
			telechips,pmap-name = "ramoops";
			alloc-ranges = <RESERVED_MEM_BASE RESERVED_MEM_SIZE>;
			size = <PMAP_SIZE_RAMOOPS>;
			no-map;
		};

		/*
		reserved_cma: linux,cma {
			compatible = "shared-dma-pool";
			alloc-ranges = <RESERVED_MEM_BASE RESERVED_MEM_SIZE>;
			size = <PMAP_SIZE_CMA>;
			//alignment = <0x04000000>;
			alignment = <0x0>;
			linux,cma-default;
			reusable;
		};
		*/

		/*-----------------------------------------------------------
		 * Shared Memory with pmap_video :: only for enc_main pmap.
		 *-----------------------------------------------------------
		 */
		pmap_enc_main: enc_main {
			compatible = "telechips,pmap";
			telechips,pmap-name = "enc_main";
			alloc-ranges = <RESERVED_MEM_BASE RESERVED_MEM_SIZE>;
			telechips,pmap-shared = <&pmap_video>;
			telechips,pmap-shared-size = <PMAP_SIZE_ENC>;
			telechips,pmap-offset = <VIDEO_MAIN_SIZE>;
			size = <0x0>;
			no-map;
		};

		pmap_enc_ext: enc_ext {
			compatible = "telechips,pmap";
			telechips,pmap-name = "enc_ext";
			alloc-ranges = <RESERVED_MEM_BASE RESERVED_MEM_SIZE>;
			size = <PMAP_SIZE_ENC_EXT>;
			no-map;
		};

		pmap_enc_ext2: enc_ext2 {
			compatible = "telechips,pmap";
			telechips,pmap-name = "enc_ext2";
			alloc-ranges = <RESERVED_MEM_BASE RESERVED_MEM_SIZE>;
			size = <PMAP_SIZE_ENC_EXT2>;
			no-map;
		};

		pmap_enc_ext3: enc_ext3 {
			compatible = "telechips,pmap";
			telechips,pmap-name = "enc_ext3";
			alloc-ranges = <RESERVED_MEM_BASE RESERVED_MEM_SIZE>;
			size = <PMAP_SIZE_ENC_EXT3>;
			no-map;
		};

		pmap_svm: pmap_svm {
			compatible = "telechips,pmap";
			telechips,pmap-name = "pmap_svm";
			alloc-ranges = <RESERVED_MEM_BASE RESERVED_MEM_SIZE>;
			size = <PMAP_SVM_SIZE>;
			no-map;
		};

		reserved_optee: optee_os {
			compatible = "optee.os";
			reg = <0x83400000 0x00C00000>;
			no-map;
			status = "disabled";
		};

		/*
		quickboot: quickboot {
		   compatible = "telechips,pmap";
		   telechips,pmap-name = "quickboot";
		   alloc-ranges = <RESERVED_MEM_BASE RESERVED_MEM_SIZE>;
		   size = <0x01800000>;
		   no-map;
		};
		*/

	};

	/*
	 * Telechips DataSheet Part2. SMU & PMU
	 */

	timer@74300080 {
		compatible = "telechips,timer32";
		reg = <0x74300080 0x1c>;
		interrupts = <GIC_SPI 1 0>;
		clocks = <&clk_peri PERI_TCZ>;
	};

	timer@74300000 { /* tc0~tc5 */
		compatible = "telechips,timer";
		reg = <0x74300000 0x60 0x74300060 0x4>;
		interrupts = <GIC_SPI 0 0>;
		clocks = <&clk_peri PERI_TCT>;
		clock-frequency = <12000000>;
	};

	watchdog@74400008 {
		compatible = "telechips,wdt";
		reg = <0x74400008 0x4>,	/* wdt_ctrl */
			  <0x74400008 0x4>,	/* wdt_cnt */
			  <0x74400008 0x4>,	/* wdt_clear */
			  <0x74300070 0xC>,	/* wdt_timer */
			  <0x74300060 0x4>;	/* wdt_int_sts */
		clocks = <&clk_peri PERI_TCX &clk_peri PERI_TCT>;
		clock-frequency = <366>; /* 24000000/65536 */
		interrupts = <GIC_SPI 0 0>;
		int-offset = <6>;
		clear-bit = <30>;
		status = "okay";
	};

	reboot_mode: reboot-mode {
		compatible = "telechips,reboot-mode";
		reg = <0x7440001c 0x4>;
		mode-normal = <BOOT_NORMAL>;
	};

	tcc-restart {
		compatible = "telechips,restart";
		reg = <0x74400000 0x1a0>;
		status = "okay";
	};

	pinctrl: pinctrl@74200000 {
		compatible = "telechips,tcc897x-pinctrl";
		reg = <0x74200000 0x300>;
		gpio-controller;
		#address-cells = <1>;
		#size-cells = <2>;
		#gpio-cells = <3>;
		interrupts = <GIC_SPI 3 0>,
		             <GIC_SPI 4 0>,
		             <GIC_SPI 5 0>,
		             <GIC_SPI 6 0>,
		             <GIC_SPI 7 0>,
		             <GIC_SPI 8 0>,
		             <GIC_SPI 9 0>,
		             <GIC_SPI 10 0>,
		             <GIC_SPI 11 0>,
		             <GIC_SPI 12 0>,
		             <GIC_SPI 13 0>,
		             <GIC_SPI 14 0>;
	};

	rtc {
		compatible = "telechips,rtc";
		reg = <0x76062000 0x50>;
		clocks = <&clk_io IOBUS_RTC &clk_isoip_top ISOIP_TOP_RTC>;
		interrupts = <GIC_SPI 43 0>;
	};

	/* sensors */
	gsensor1@76300038 {
		compatible = "bosch, bma150", "bosch, bma023";
	};

	gsensor2@7630000B {
		compatible = "bosch, bma220";
	};

	gsensor3@76300018 {
		compatible = "bosch, bma250";
	};

	i2c0: i2c@76300000 {
		compatible = "telechips,tcc897x-i2c";
		reg = <0x76300000 0x1c 0x76360000 0x010>;
		interrupts = <GIC_SPI 38 IRQ_TYPE_LEVEL_HIGH>;
		#address-cells = <1>;
		#size-cells = <0>;
		clocks = <&clk_peri PERI_I2C0 &clk_io IOBUS_I2C_M0>;
		clock-frequency = <400000>;
		port-mux = <0xFF>;	/* default value */
		status = "disabled";
		interrupt_mode = <0>;
	};

	i2c1: i2c@76310000 {
		compatible = "telechips,tcc897x-i2c";
		reg = <0x76310000 0x1c 0x76360000 0x10>;
		interrupts = <GIC_SPI 38 IRQ_TYPE_LEVEL_HIGH>;
		#address-cells = <1>;
		#size-cells = <0>;
		clocks = <&clk_peri PERI_I2C1 &clk_io IOBUS_I2C_M1>;
		/*Set HDMI I2C frequency to 80Khz*/
		clock-frequency = <80000>;
		port-mux = <0xFF>;	/* default value */
		status = "disabled";
		interrupt_mode = <0>;
	};

	i2c2: i2c@76320000 {
		compatible = "telechips,tcc897x-i2c";
		reg = <0x76320000 0x1c 0x76360000 0x10>;
		interrupts = <GIC_SPI 38 IRQ_TYPE_LEVEL_HIGH>;
		#address-cells = <1>;
		#size-cells = <0>;
		clocks = <&clk_peri PERI_I2C2 &clk_io IOBUS_I2C_M2>;
		clock-frequency = <400000>;
		port-mux = <0xFF>;	/* default value */
		status = "disabled";
		interrupt_mode = <0>;
	};

	i2c3: i2c@76330000 {
		compatible = "telechips,tcc897x-i2c";
		reg = <0x76330000 0x1c 0x76360000 0x10>;
		interrupts = <GIC_SPI 38 IRQ_TYPE_LEVEL_HIGH>;
		#address-cells = <1>;
		#size-cells = <0>;
		clocks = <&clk_peri PERI_I2C3 &clk_io IOBUS_I2C_M3>;
		clock-frequency = <400000>;
		port-mux = <0xFF>;	/* default value */
		status = "disabled";
		interrupt_mode = <0>;
	};

	i2cslave0: i2cslave@76340000 {
		compatible = "telechips,tcc897x-i2c-slave";
		reg = <0x76340000 0x28 0x76360000 0x10>;
		interrupts = <GIC_SPI 38 IRQ_TYPE_LEVEL_HIGH>;
		#address-cells = <1>;
		#size-cells = <0>;
		clocks = <&clk_io IOBUS_I2C_S0>;
		id = <0>;
		status = "disabled";
		/* USE DMA-engine */
		//dmas = <&dma0 0 25>, <&dma0 1 19>;
		//dma-names = "tx", "rx";
	};

	i2cslave1: i2cslave@76350000 {
		compatible = "telechips,tcc897x-i2c-slave";
		reg = <0x76350000 0x28 0x76360000 0x10>;
		interrupts = <GIC_SPI 38 IRQ_TYPE_LEVEL_HIGH>;
		#address-cells = <1>;
		#size-cells = <0>;
		clocks = <&clk_io IOBUS_I2C_S1>;
		id = <1>;
		status = "disabled";
		/* USE DMA-engine */
		//dmas = <&dma0 0 57>, <&dma0 1 51>;
		//dma-names = "tx", "rx";
	};

	i2cslave2: i2cslave@76351000 {
		compatible = "telechips,tcc897x-i2c-slave";
		reg = <0x76351000 0x28 0x76360000 0x10>;
		interrupts = <GIC_SPI 38 IRQ_TYPE_LEVEL_HIGH>;
		#address-cells = <1>;
		#size-cells = <0>;
		clocks = <&clk_io IOBUS_I2C_S2>;
		id = <2>;
		status = "disabled";
	};

	i2cslave3: i2cslave@76352000 {
		compatible = "telechips,tcc897x-i2c-slave";
		reg = <0x76352000 0x28 0x76360000 0x10>;
		interrupts = <GIC_SPI 38 IRQ_TYPE_LEVEL_HIGH>;
		#address-cells = <1>;
		#size-cells = <0>;
		clocks = <&clk_io IOBUS_I2C_S3>;
		id = <3>;
		status = "disabled";
	};

	/*
	 * Graphic Bus Block
	 */

	gpu@70000000 {
		compatible = "arm,mali-400", "arm,mali-utgard";
		reg = <0x70000000 0x10000>;
		interrupts = <GIC_SPI 25 IRQ_TYPE_LEVEL_HIGH>,
		             <GIC_SPI 17 IRQ_TYPE_LEVEL_HIGH>,
		             <GIC_SPI 24 IRQ_TYPE_LEVEL_HIGH>,
		             <GIC_SPI 16 IRQ_TYPE_LEVEL_HIGH>,
		             <GIC_SPI 35 IRQ_TYPE_LEVEL_HIGH>,
		             <GIC_SPI 40 IRQ_TYPE_LEVEL_HIGH>,
		             <GIC_SPI 26 IRQ_TYPE_LEVEL_HIGH>;
		interrupt-names = "IRQGP", "IRQGPMMU", "IRQPP0", "IRQPPMMU0",
		                  "IRQPP1", "IRQPPMMU1", "IRQPMU";
		shared_mem_size = <512>;
		clocks = <&clk_fbus FBUS_GPU>;
		clock-names = "mali_clk";
	};

	telechips,ion {
		compatible = "telechips,tcc-ion";
		#address-cells = <1>;
		#size-cells = <0>;
/*
		ion-heap@0 {
			reg = <0>;
			telechips,ion-heap-name = "ion_noncontig_heap";
		};

		ion-heap@1 {
			reg = <1>;
			telechips,ion-heap-name = "ion_contig_heap";
		};
*/
		ion-heap@2 {
			reg = <2>;
			telechips,ion-heap-name = "ion_carveout_heap";
		};

		ion-heap@3 {
                        reg = <3>;
                        telechips,ion-heap-name = "ion_carveout_cam_heap";
		};

	};

	/*
	 * Memory Bus Block
	 */


	/*
	 * I/O Bus Block
	 */

	dma0: dma@76030000 {
		compatible = "telechips,tcc897x-dma";
		reg = <0x76030000 0x94 0x76066004 0x4>;
		interrupts = <GIC_SPI 29 0>;
		#dma-cells = <2>;
		dma-channels = <3>;
		dma-requests = <32>;
		clocks = <&clk_io IOBUS_DMA0>;
		clock-names = "dmac0";
	};

	dma1: dma@76030100 {
		compatible = "telechips,tcc897x-dma";
		reg = <0x76030100 0x94 0x76066008 0x4>;
		interrupts = <GIC_SPI 29 0>;
		#dma-cells = <2>;
		dma-channels = <3>;
		dma-requests = <32>;
		clocks = <&clk_io IOBUS_DMA1>;
		clock-names = "dmac1";
	};

	dma2: dma@76030200 {
		compatible = "telechips,tcc897x-dma";
		reg = <0x76030200 0x94 0x7606600C 0x4>;
		interrupts = <GIC_SPI 29 0>;
		#dma-cells = <2>;
		dma-channels = <3>;
		dma-requests = <32>;
		clocks = <&clk_io IOBUS_DMA2>;
		clock-names = "dmac2";
	};

	dma3: dma@76040000 {
		compatible = "telechips,tcc897x-dma";
		reg = <0x76040000 0x94 0x76066060 0x4>;
		interrupts = <GIC_SPI 96 0>;
		#dma-cells = <2>;
		dma-channels = <3>;
		dma-requests = <32>;
		clocks = <&clk_io IOBUS_DMAC0>;
		clock-names = "dmac3";
	};

	dma4: dma@76040100 {
		compatible = "telechips,tcc897x-dma";
		reg = <0x76040100 0x94 0x76066064 0x4>;
		interrupts = <GIC_SPI 96 0>;
		#dma-cells = <2>;
		dma-channels = <3>;
		dma-requests = <32>;
		clocks = <&clk_io IOBUS_DMAC1>;
		clock-names = "dmac4";
	};

	pwm@76050000 { /* pwm */
		compatible = "telechips,pwm";
		reg = <0x76050000 0x70 0x7606605C 0x4>;
		tcc,pwm-number = <4>;
		#pwm-cells = <2>;
		clocks = <&clk_peri PERI_PDM &clk_io IOBUS_PWM>;
		status = "okay";
	};

	uart0: serial@76370000 {
		compatible = "telechips,tcc897x-uart";
		reg = <0x76370000 0x84>;
		interrupt-parent = <&gic>;
		interrupts = <GIC_SPI 47 0>;
		clocks = <&clk_io IOBUS_UART0 &clk_peri PERI_UART0>;
		status = "disabled";
	};

	uart1: serial@76380000 {
		compatible = "telechips,tcc897x-uart";
		reg = <0x76380000 0x84>;
		interrupt-parent = <&gic>;
		interrupts = <GIC_SPI 47 0>;
		clocks = <&clk_io IOBUS_UART1 &clk_peri PERI_UART1>;
		status = "disabled";
	};

	uart2: serial@76390000 {
		compatible = "telechips,tcc897x-uart";
		reg = <0x76390000 0x84>;
		interrupt-parent = <&gic>;
		interrupts = <GIC_SPI 47 0>;
		clocks = <&clk_io IOBUS_UART2 &clk_peri PERI_UART2>;
		status = "disabled";
	};

	uart3: serial@763a0000 {
		compatible = "telechips,tcc897x-uart";
		reg = <0x763a0000 0x84>;
		interrupt-parent = <&gic>;
		interrupts = <GIC_SPI 47 0>;
		clocks = <&clk_io IOBUS_UART3 &clk_peri PERI_UART3>;
		status = "disabled";
	};

	uart4: serial@763b0000 {
		compatible = "telechips,tcc897x-uart";
		reg = <0x763b0000 0x84>;
		interrupt-parent = <&gic>;
		interrupts = <GIC_SPI 47 0>;
		clocks = <&clk_io IOBUS_UART4 &clk_peri PERI_UART4>;
		status = "disabled";
	};

	uart5: serial@763c0000 {
		compatible = "telechips,tcc897x-uart";
		reg = <0x763c0000 0x84>;
		interrupt-parent = <&gic>;
		interrupts = <GIC_SPI 47 0>;
		clocks = <&clk_io IOBUS_UART5 &clk_peri PERI_UART5>;
		status = "disabled";
	};

	uart6: serial@763d0000 {
		compatible = "telechips,tcc897x-uart";
		reg = <0x763d0000 0x84>;
		interrupt-parent = <&gic>;
		interrupts = <GIC_SPI 47 0>;
		clocks = <&clk_io IOBUS_UART6 &clk_peri PERI_UART6>;
		status = "disabled";
	};

	uart7: serial@763e0000 {
		compatible = "telechips,tcc897x-uart";
		reg = <0x763e0000 0x84>;
		interrupt-parent = <&gic>;
		interrupts = <GIC_SPI 47 0>;
		clocks = <&clk_io IOBUS_UART7 &clk_peri PERI_UART7>;
		status = "disabled";
	};

	hdmi@72300000 {
		compatible = "telechips,tcc897x-hdmi";
		reg = <0x72300000 0x100 0x72310000 0x7000 0x72360000 0x100>;
		reg-names = "hdmi_ctrl", "hdmi_core";
		interrupt-parent = <&gic>;
		interrupts = <GIC_SPI 34 IRQ_TYPE_LEVEL_HIGH>;
		clocks = <&clk_peri PERI_HDMI &clk_ddi DDIBUS_HDMI &clk_peri PERI_HDMI_PCLK>;
		clock-frequency = <24000000>;
		vioc-frequency = <27>;
		status = "disabled";
	};

	hpd@72310000 {
		compatible = "telechips,tcc897x-hdmi-hpd";
		pinctrl-names = "default";
		pinctrl-0 = <&hdmi_hpd>;
		gpios = <&gphdmi 1 0>;
		status = "disabled";
	};

	audio@72330000 {
		compatible = "telechips,tcc897x-hdmi-audio";
		reg = <0x72300000 0x100 0x72330000 0x100 0x72340000 0x100>;
		reg-names = "hdmi_ctrl", "hdmi_spdif", "hdmi_i2s";
		interrupt-parent = <&gic>;
		interrupts = <GIC_SPI 34 IRQ_TYPE_LEVEL_HIGH>;
		clocks = <&clk_peri PERI_HDMIA &clk_ddi DDIBUS_HDMI>;
		status = "disabled";
	};

	cec@72370000 {
		compatible = "telechips,tcc897x-hdmi-cec";
		reg = <0x72300000 0x100 0x72350000 0x200>;
		reg-names = "hdmi_ctrl", "hdmi_cec";
		pinctrl-names = "default";
		pinctrl-0 = <&hdmi_cec>;
		interrupt-parent = <&gic>;
		interrupts = <GIC_SPI 34 IRQ_TYPE_LEVEL_HIGH>;
		clocks = <&clk_peri PERI_HDMI &clk_ddi DDIBUS_HDMI &clk_peri PERI_HDMI_PCLK>;
		clock-frequency = <24000000>;
		status = "disabled";
	};

	adc@76064000 {
		compatible = "telechips,adc";
		reg = <0x76064000 0x24 0x7440000C 0x4>;
		clocks = <&clk_peri PERI_ADC &clk_io IOBUS_TSADC &clk_isoip_top ISOIP_TOP_TSADC>;
		clock-frequency = <12000000>;
		ckin-frequency  = <1000000>;
		adc-12bit-resolution;
		adc-delay = <150>;
		status = "okay";
	};

	tsadc@76064000 {	/* ADC Touch Screen */
		compatible = "telechips,tsadc";
		reg = <0x76064000 0x24>;
		int-gpios = <&gpadc 6 0>;	/* for using TSADC_UPDOWN extint soruce */
		status = "disabled";
	};

	sdhc3: sdhc@76020600 {
		compatible = "telechips,tcc897x-sdhc";
		reg = <0x76020600 0x100>, <0x76020800 0x80>;
		interrupts = <GIC_SPI 32 IRQ_TYPE_LEVEL_HIGH>;
		clocks = <&clk_peri PERI_SDMMC3 &clk_io IOBUS_SDMMC3>;
		clock-names = "mmc_fclk", "mmc_hclk";
		max-frequency = <48000000>;
		/*cap-sd-highspeed;*/
		/*cap-mmc-highspeed;*/
		bus-width = <4>;
		status = "disabled";
	};

	sdhc0: sdhc@76020000 {
		compatible = "telechips,tcc897x-sdhc";
		reg = <0x76020000 0x100>, <0x76020800 0x80>;
		interrupts = <GIC_SPI 44 IRQ_TYPE_LEVEL_HIGH>;
		clocks = <&clk_peri PERI_SDMMC0 &clk_io IOBUS_SDMMC0>;
		clock-names = "mmc_fclk", "mmc_hclk";
		max-frequency = <48000000>;
		/*cap-sd-highspeed;*/
		/*cap-mmc-highspeed;*/
		bus-width = <4>;
		status = "disabled";
	};

	sdhc2: sdhc@76020400 {
		compatible = "telechips,tcc897x-sdhc";
		reg = <0x76020400 0x100>, <0x76020800 0x80>;
		interrupts = <GIC_SPI 33 IRQ_TYPE_LEVEL_HIGH>;
		clocks = <&clk_peri PERI_SDMMC2 &clk_io IOBUS_SDMMC2>;
		clock-names = "mmc_fclk", "mmc_hclk";
		max-frequency = <48000000>;
		/*cap-sd-highspeed;*/
		/*cap-mmc-highspeed;*/
		bus-width = <4>;
		status = "disabled";
	};

	nand: nand@76600000 {
		compatible = "telechips,nand-v8";
		reg = <0x76600000 0x13ff>;
		interrupt-parent = <&gic>;
		interrupts = <GIC_SPI 41 IRQ_TYPE_LEVEL_HIGH>;
		status = "disabled";
	};

	remote@76070000 {
		compatible = "telechips,tccxxxx-remote";
		status = "disabled";
		interrupts = <GIC_SPI 42 IRQ_TYPE_LEVEL_HIGH>;
		clocks = <&clk_peri PERI_REMOTE &clk_io IOBUS_REMOCON>;
		clock-frequency = <24000000>;
	};

	gpsb0: gpsb0@76900000 {
		compatible = "telechips,tcc897x-spi";
		reg = <0x76900000 0x38 0x76960000 0x10 0x76970000 0x84>;
		interrupts = <GIC_SPI 36 IRQ_TYPE_LEVEL_HIGH>;
		clocks = <&clk_peri PERI_GPSB0 &clk_io IOBUS_GPSB0>;
		gpsb-id = <0>;
		status = "disabled";
	};

	gpsb1: gpsb1@76910000 {
		compatible = "telechips,tcc897x-tsif";
		reg = <0x76910000 0x38 0x76960000 0x10 0x76970000 0x84>;
		interrupts = <GIC_SPI 36 IRQ_TYPE_LEVEL_HIGH>;
		clocks = <&clk_peri PERI_GPSB1 &clk_io IOBUS_GPSB1>;
		gpsb-id = <0>;
		status = "disabled";
	};

	gpsb2: gpsb2@76920000 {
		compatible = "telechips,tcc897x-tsif";
		reg = <0x76920000 0x38 0x76960000 0x10 0x76970000 0x84>;
		interrupts = <GIC_SPI 36 IRQ_TYPE_LEVEL_HIGH>;
		clocks = <&clk_peri PERI_GPSB2 &clk_io IOBUS_GPSB2>;
		gpsb-id = <1>;
		status = "disabled";
	};

	pcm0: pcm@76200000 {
		compatible = "telechips,pcm";
		reg = <0x76200000 0x160 0x76200100 0x50 0x76201080 0x24 0x76202000 0x1000>;
		clocks = <&clk_io IOBUS_ADMA0>;
		interrupts = <GIC_SPI 60 IRQ_TYPE_LEVEL_HIGH>;
		status = "disabled";
	};

	pcm1: pcm@76100000 {
		compatible = "telechips,pcm";
		reg = <0x76100000 0x80>;
		clocks = <&clk_io IOBUS_ADMA3>;
		interrupts = <GIC_SPI 58 IRQ_TYPE_LEVEL_HIGH>;
		status = "disabled";
	};

	adma0: adma@76200000{
		compatible = "telechips,adma";
		reg = <0x76200000 0x200>;
		interrupts = <GIC_SPI 60 IRQ_TYPE_LEVEL_HIGH>;
	};

	adma1: adma@76400000{
		compatible = "telechips,adma";
		reg = <0x76400000 0x200>;
		interrupts = <GIC_SPI 97 IRQ_TYPE_LEVEL_HIGH>;
	};

	adma2: adma@76b00000{
		compatible = "telechips,adma";
		reg = <0x76b00000 0x200>;
		interrupts = <GIC_SPI 99 IRQ_TYPE_LEVEL_HIGH>;
	};

	adma3: adma@76100000{
		compatible = "telechips,adma";
		reg = <0x76100000 0x200>;
		interrupts = <GIC_SPI 58 IRQ_TYPE_LEVEL_HIGH>;
	};

	i2s0: i2s@76201000 {
		compatible = "telechips,i2s";
		reg = <0x76201000 0x50>;
		clocks = <&clk_peri PERI_ADAI0 &clk_io IOBUS_DAI0>;
		clock-frequency = <11289600>;	// 44100*256
		adma = <&adma0>;
		status = "disabled";
	};

	i2s1: i2s@76401000 {
		compatible = "telechips,i2s";
		reg = <0x76401000 0x50>;
		clocks = <&clk_peri PERI_ADAI1 &clk_io IOBUS_DAI1>;
		clock-frequency = <11289600>;
		adma = <&adma1>;
		status = "disabled";
	};

	i2s2: i2s@76b01000 {
		compatible = "telechips,i2s";
		reg = <0x76b01000 0x50>;
		clocks = <&clk_peri PERI_ADAI2 &clk_io IOBUS_DAI2>;
		clock-frequency = <11289600>;
		adma = <&adma2>;
		status = "disabled";
	};

	i2s3: i2s@76101000 {
		compatible = "telechips,i2s";
		reg = <0x76101000 0x50>;
		clocks = <&clk_peri PERI_ADAI3 &clk_io IOBUS_DAI3>;
		clock-frequency = <11289600>;
		adma = <&adma3>;
		status = "disabled";
	};

	i2s10: i2s@10 {
		compatible = "telechips,i2s_dummy";
		reg = <0x76d01000 0x50>;
		status = "disabled";
	};

	i2s11: i2s@11 {
		compatible = "telechips,i2s_dummy";
		reg = <0x76f01000 0x50>;
		status = "disabled";
	};

	i2s12: i2s@12 {
		compatible = "telechips,i2s_dummy";
		reg = <0x76f02000 0x50>;
		status = "disabled";
	};

	i2s13: i2s@13 {
		compatible = "telechips,i2s_dummy";
		reg = <0x76f03000 0x50>;
		status = "disabled";
	};

	spdif0: spdif@76202000 {
		compatible = "telechips,spdif";
		reg = <0x76202000 0x1000>;
		clocks = <&clk_peri PERI_SPDIF0 &clk_io IOBUS_SPDIF0>;
		clock-frequency = <44100>;
		adma = <&adma0>;
		status = "disabled";
	};

	spdif1: spdif@76102000 {
		compatible = "telechips,spdif";
		reg = <0x76102000 0x6E0>;
		clocks = <&clk_peri PERI_SPDIF3 &clk_io IOBUS_SPDIF3>;
		clock-frequency = <44100>;
		adma = <&adma3>;
		status = "disabled";
	};

	cdif0: cdif@76201080 {
		compatible = "telechips,cdif";
		reg = <0x76201080 0x24>;
		clocks = <&clk_peri PERI_ADAM0>;
		clock-frequency = <44100>;
		adma = <&adma0>;
		status = "disabled";
	};

	cdif1: cdif@76101080 {
		compatible = "telechips,cdif";
		reg = <0x76101080 0x24>;
		clocks = <&clk_peri PERI_ADAM3>;
		clock-frequency = <44100>;
		adma = <&adma3>;
		status = "disabled";
	};

	/*
	 * HSIO Bus Block
	 */

	gmac@71600000{
		compatible = "telechips,gmac";
		reg = <0x71600000 0x3000>;
		interrupts = <GIC_SPI 50 IRQ_TYPE_LEVEL_HIGH>;
		status = "disabled";
		index = <0>;
		clocks = <&clk_peri PERI_GMAC &clk_fbus FBUS_HSIO &clk_peri PERI_GMAC_PTP &clk_hsio HSIOBUS_GMAC>; //PERI_GMAC0, HSIOBUS, PERI_PTP0, HCLK_GMAC
		clock-names = "gmac-pclk", "hsio-clk", "ptp-pclk", "gmac-hclk";
	};

	trng@71EB0100 {
		compatible = "telechips,tcc-rng";
		reg = <0x71EB0100 0x100>;
		clocks = <&clk_hsio HSIOBUS_TRNG>;
		status = "okay";
	};

	dwc_otg_phy:dwc_otg_phy@71EA0100 {
		compatible = "telechips,tcc_dwc_otg_phy";
		reg = <0x71EA0100 0x20>;
		/* otg_hclk=0xe0+0, otg_phy=0x10+9*/
		clocks = <&clk_hsio HSIOBUS_USBOTG &clk_isoip_top ISOIP_TOP_USBOTG>;
		status = "disabled";
	};

	dwc_otg: dwc_otg@71B00000 {
		compatible = "telechips,dwc2";
		reg = <0x71B00000 0xcfff>;
		interrupts = <GIC_SPI 48 IRQ_TYPE_LEVEL_HIGH>;
		clocks = <&clk_hsio HSIOBUS_USBOTG>;
		clock-names = "otg";
		phy = <&dwc_otg_phy>;
		phy-names = "usb2-phy";
		status= "disabled";
	};

	ehci_phy:ehci_phy@71EA0010 {
		compatible = "telechips,tcc_ehci_phy";
		reg = <0x71EA0010 0x30>;
		/* otg_hclk=0xe0+0, otg_phy=0x10+9*/
		clocks = <&clk_hsio HSIOBUS_USB20H &clk_isoip_top ISOIP_TOP_USB2P>;
		status = "disabled";
	 };

	ohci@71300000 {
		compatible = "telechips,tcc-ohci";
		reg = <0x71300000 0x1000 0x71EA0010 0x1000>;
		interrupts = <GIC_SPI 49 IRQ_TYPE_LEVEL_HIGH>;
		clocks = <&clk_hsio HSIOBUS_USB20H &clk_isoip_top ISOIP_TOP_USB2P>;
		status = "disabled";
		tpl-support; // Support TPL
	};

	ehci:ehci@71200000 {
		compatible = "telechips,tcc-ehci";
		reg = <0x71200000 0x1000 0x71EA0010 0x1000>;
		interrupts = <GIC_SPI 49 IRQ_TYPE_LEVEL_HIGH>;
		clocks = <&clk_hsio HSIOBUS_USB20H &clk_isoip_top ISOIP_TOP_USB2P>;
		telechips,ehci_phy = <&ehci_phy>;
		status = "disabled";
		tpl-support; // Support TPL
	};

	tcc_cipher@71ec0000 {
		compatible = "telechips,tcc-cipher";
		reg = <0x71EC0000 0x1E0 0x74100000 0x10C>; //HSIO_Cipher , VPIC(VECTORED PRIORITY INTERRUPT CONTROLLER)
		interrupts = <GIC_SPI 52 IRQ_TYPE_LEVEL_HIGH>;
		clocks = <&clk_hsio HSIOBUS_CIPHER>; //HSIOBUS_CIPHER
		status = "disabled";
	};

	/*
	 * Display Bus Block
	 */
	cifport: cifport@7238000c {
		compatible = "telechips,cif-port";
		reg = <0x7238000c 0x4>;
		statue = "okay";
	};

	lvds@72380040 {
		compatible = "telechips,lvds_phy";
		reg = <0x72380040 0x64>;
		clocks = <&clk_isoip_top ISOIP_TOP_LVDS>;
		statue = "disable";
	};

	overlaymixer:overlaymixer@72400000 {
		compatible = "vivante.gc";
		reg = <0x72400000 0x1000>;
		interrupts = <GIC_SPI 27 IRQ_TYPE_LEVEL_HIGH>;
		clocks =<&clk_fbus FBUS_G2D &clk_ddi DDIBUS_G2D>;
		status ="disabled";
	};

	vioc_config:vioc_config@7200a000{
		compatible = "telechips,vioc_config";
		reg = <0x7200a000 0x1000>;
	};

	ddi_config: ddi_config@72380000 {
		compatible = "telechips,ddi_config";
		reg = <0x72380000 0x70>;
	};

	output_config: output_config@72100200 {
		compatible = "telechips,output_config";
		reg = <0x72100200 0x10>;
	};

	vioc_disp:vioc_disp@72000000{
		compatible = "telechips,vioc_disp";
		reg = <0x72000000 0x100 0x72000100 0x100>;
		interrupts = <GIC_SPI 20 IRQ_TYPE_LEVEL_HIGH>, <GIC_SPI 20 IRQ_TYPE_LEVEL_HIGH>;
		clocks = <&clk_ddi DDIBUS_VIOC>, <&clk_peri PERI_LCD0>, <&clk_peri PERI_LCD1>;
		clock-names = "ddi-clk", "disp0-clk", "disp1-clk";
	};

	vioc_display0:vioc_display0@72000000{
		compatible = "telechips,vioc_display0";
		reg = <0x72000000 0x100>;
		interrupts = <GIC_SPI 20 IRQ_TYPE_LEVEL_HIGH>;
		clocks = <&clk_ddi DDIBUS_VIOC &clk_peri PERI_LCD0>;
		disp_number = <0>;
	};

	vioc_display1:vioc_display1@72000000{
		compatible = "telechips,vioc_display1";
		reg = <0x72000100 0x100>;
		interrupts = <GIC_SPI 20 IRQ_TYPE_LEVEL_HIGH>;
		clocks = <&clk_ddi DDIBUS_VIOC &clk_peri PERI_LCD1>;
		disp_number = <1>;
	};

	vioc_rdma:vioc_rdma@72000400{
		compatible = "telechips,vioc_rdma";
		reg = <0x72000400 0x100 0x72000500 0x100 0x72000600 0x100 0x72000700 0x100
		       0x72000800 0x100 0x72000900 0x100 0x72000a00 0x100 0x72000b00 0x100
		       0x72000c00 0x100 0x72000d00 0x100 0x72000e00 0x100 0x72000f00 0x100
		       0x72001000 0x100 0x72001100 0x100 0x72001200 0x100 0x72001300 0x100
		       0x72001400 0x100 0x72001500 0x100>;
		interrupts = <GIC_SPI 20 IRQ_TYPE_LEVEL_HIGH>,
		             <GIC_SPI 20 IRQ_TYPE_LEVEL_HIGH>,
		             <GIC_SPI 20 IRQ_TYPE_LEVEL_HIGH>,
		             <GIC_SPI 20 IRQ_TYPE_LEVEL_HIGH>,
		             <GIC_SPI 20 IRQ_TYPE_LEVEL_HIGH>,
		             <GIC_SPI 20 IRQ_TYPE_LEVEL_HIGH>,
		             <GIC_SPI 20 IRQ_TYPE_LEVEL_HIGH>,
		             <GIC_SPI 20 IRQ_TYPE_LEVEL_HIGH>,
		             <GIC_SPI 20 IRQ_TYPE_LEVEL_HIGH>,
		             <GIC_SPI 20 IRQ_TYPE_LEVEL_HIGH>,
		             <GIC_SPI 20 IRQ_TYPE_LEVEL_HIGH>,
		             <GIC_SPI 20 IRQ_TYPE_LEVEL_HIGH>,
		             <GIC_SPI 20 IRQ_TYPE_LEVEL_HIGH>,
		             <GIC_SPI 20 IRQ_TYPE_LEVEL_HIGH>,
		             <GIC_SPI 20 IRQ_TYPE_LEVEL_HIGH>,
		             <GIC_SPI 20 IRQ_TYPE_LEVEL_HIGH>,
		             <GIC_SPI 20 IRQ_TYPE_LEVEL_HIGH>,
		             <GIC_SPI 20 IRQ_TYPE_LEVEL_HIGH>;
	};

	vioc_wmix:vioc_wmix@72001800{
		compatible = "telechips,vioc_wmix";
		reg = <0x72001800 0x100 0x72001900 0x100 0x72001a00 0x100 0x72001b00 0x100
				0x72001c00 0x100 0x72001d00 0x100 0x72001e00 0x100>;
		interrupts = <GIC_SPI 20 IRQ_TYPE_LEVEL_HIGH>,
		             <GIC_SPI 20 IRQ_TYPE_LEVEL_HIGH>,
		             <GIC_SPI 20 IRQ_TYPE_LEVEL_HIGH>,
		             <GIC_SPI 20 IRQ_TYPE_LEVEL_HIGH>,
		             <GIC_SPI 20 IRQ_TYPE_LEVEL_HIGH>,
		             <GIC_SPI 20 IRQ_TYPE_LEVEL_HIGH>,
		             <GIC_SPI 20 IRQ_TYPE_LEVEL_HIGH>;
	};

	vioc_scaler:vioc_scaler@72002000{
		compatible = "telechips,scaler";
		reg = <0x72002000 0x100 0x72002100 0x100 0x72002200 0x100 0x72002300 0x100>;
		status = "disabled";
	};

	vioc_wdma:vioc_wdma@72002800{
		compatible = "telechips,vioc_wdma";
		reg = <0x72002800 0x700 0x72002900 0x100 0x72002a00 0x100 0x72002b00 0x100
		       0x72002c00 0x100 0x72002d00 0x100 0x72002e00 0x100 0x72002f00 0x100
		       0x72003000 0x100 >;
		interrupts = <GIC_SPI 20 IRQ_TYPE_LEVEL_HIGH>,
		             <GIC_SPI 20 IRQ_TYPE_LEVEL_HIGH>,
		             <GIC_SPI 20 IRQ_TYPE_LEVEL_HIGH>,
		             <GIC_SPI 20 IRQ_TYPE_LEVEL_HIGH>,
		             <GIC_SPI 20 IRQ_TYPE_LEVEL_HIGH>,
		             <GIC_SPI 20 IRQ_TYPE_LEVEL_HIGH>,
		             <GIC_SPI 20 IRQ_TYPE_LEVEL_HIGH>,
		             <GIC_SPI 20 IRQ_TYPE_LEVEL_HIGH>,
		             <GIC_SPI 20 IRQ_TYPE_LEVEL_HIGH>;
	};

	vioc_vin:vioc_vin@72004000{
		compatible = "telechips,vioc_vin";
		reg = < 0x72004000 0x400 0x72004400 0x600
			0x72005000 0x400 0x72005400 0x600
			0x72006000 0x400 0x72006400 0x600
			0x72007000 0x400 0x72007400 0x600>;
		interrupts = <GIC_SPI 20 IRQ_TYPE_LEVEL_HIGH>,
		             <GIC_SPI 20 IRQ_TYPE_LEVEL_HIGH>,
		             <GIC_SPI 20 IRQ_TYPE_LEVEL_HIGH>,
		             <GIC_SPI 20 IRQ_TYPE_LEVEL_HIGH>,
		             <GIC_SPI 20 IRQ_TYPE_LEVEL_HIGH>,
		             <GIC_SPI 20 IRQ_TYPE_LEVEL_HIGH>,
		             <GIC_SPI 20 IRQ_TYPE_LEVEL_HIGH>,
		             <GIC_SPI 20 IRQ_TYPE_LEVEL_HIGH>,
		             <GIC_SPI 20 IRQ_TYPE_LEVEL_HIGH>;
	};

	vioc_viqe:vioc_viqe@7200d000{
		compatible = "telechips,vioc_viqe";
		reg = <0x7200d000 0x1000 0x72010000 0x1000>;
	};

	viqe_hidden:viqe_hidden{
		reg = <0x7200d100 0x4 0x7200d10c 0x4>;
	};

	vioc_lut:vioc_lut@72009000{
		compatible = "telechips,vioc_lut";
		reg = <0x72009000 0x800>;
		status = "disabled";
	};

	vioc_deintls:vioc_deintls@72003800{
		compatible = "telechips,vioc_deintls";
		reg = <0x72003800 0x10>;
	};

	vioc_fifo:vioc_fifo@72003b00{
		compatible = "telechips,vioc_fifo";
		reg = <0x72003b00 0x100>;
	};

	vioc_rdma_arbitor:vioc_rdma_arbitor@72003f00{
		reg = <0x72003f00 0x20 0x72003f20 0x20 0x72003f40 0x20 0x72003f60 0x20>;
		arbitor_num = <4>;
	};

	fbdisplay: fbdisplay@72000000 {
		compatible = "telechips,vioc-fb";
		reg = <0x72000000 0x10000>;
		telechips,fbdisplay_num = <1>;
		telechips,rdma_arbitor=<&vioc_rdma_arbitor>;
		memory-region = <&pmap_fb_video &pmap_fb1_video>;

		fbdisplay0:fbdisplay0@72000000{
			telechips,disp = <&vioc_disp VIOC_DISP0>;
			telechips,wmixer = <&vioc_wmix VIOC_WMIX0>;
			telechips,rdma = <&vioc_rdma VIOC_RDMA00 VIOC_RDMA01 VIOC_RDMA02 VIOC_RDMA03>;
			telechips,wdma = <&vioc_wdma VIOC_WDMA00>;
		};

		fbdisplay1:fbdisplay1@72000100{
			telechips,disp = <&vioc_disp VIOC_DISP1>;
			telechips,wmixer = <&vioc_wmix VIOC_WMIX1>;
			telechips,rdma = <&vioc_rdma VIOC_RDMA04 VIOC_RDMA05 VIOC_RDMA06 VIOC_RDMA07>;
			telechips,wdma = <&vioc_wdma VIOC_WDMA01>;
		};
	};

	fb0: fb@0 {
		compatible = "telechips,fb";
		status = "disabled";
		memory-region = <&pmap_fb_video>;
		xres = <1920>;
		yres = <720>;
		bpp = <32>;
		mode = <FBX_TRIPLE>;
		update-type = <FBX_RDMA_UPDATE>;
		device-priority = <FBX_DEVICE_LVDS>;
		telechips,disp = <&vioc_disp VIOC_DISP0>;
		telechips,wmixer = <&vioc_wmix VIOC_WMIX0>;
		telechips,rdma = <&vioc_rdma VIOC_RDMA00>;
	};

	fb1: fb@1 {
		compatible = "telechips,fb";
		status = "disabled";
		memory-region = <&pmap_fb1_video>;
		xres = <1920>;
		yres = <720>;
		bpp = <32>;
		mode = <FBX_TRIPLE>;
		update-type = <FBX_OVERLAY_UPDATE>;
		device-priority = <FBX_DEVICE_LVDS>;
		telechips,disp = <&vioc_disp VIOC_DISP0>;
		telechips,wmixer = <&vioc_wmix VIOC_WMIX0>;
		telechips,rdma = <&vioc_rdma VIOC_RDMA01>;
		};

	fb2: fb@2 {
		compatible = "telechips,fb";
		status = "disabled";
		memory-region = <&pmap_fb2_video>;
		xres = <1920>;
		yres = <720>;
		bpp = <32>;
		mode = <FBX_TRIPLE>;
		update-type = <FBX_RDMA_UPDATE>;
		device-priority = <FBX_DEVICE_HDMI>;
		telechips,disp = <&vioc_disp VIOC_DISP1>;
		telechips,wmixer = <&vioc_wmix VIOC_WMIX1>;
		telechips,rdma = <&vioc_rdma VIOC_RDMA04>;
	};

	tcc_overlay_drv {
		compatible = "telechips,tcc_overlay";
		fbdisplay-overlay = <&fbdisplay>;
		clocks = <&clk_ddi DDIBUS_VIOC>;
		rdmas = <&vioc_rdma VIOC_RDMA00 VIOC_RDMA01 VIOC_RDMA02 VIOC_RDMA03 VIOC_RDMA04 VIOC_RDMA05 VIOC_RDMA06 VIOC_RDMA07>;
		wmixs = <&vioc_wmix VIOC_WMIX0 VIOC_WMIX1>;
		status = "okay";
	};

	tcc_video_viqe {
		compatible = "telechips,tcc_viqe";

		tcc_viqe_viqe_common {
			telechips,viqe,0 = <&vioc_viqe VIOC_VIQE0>;
			vioc_deintls = <VIOC_DEINTLS0>;
			board_num=<0>;
		};

		tcc_video_viqe_lcd {
			telechips,wmixer = <&vioc_wmix VIOC_WMIX1>;
			telechips,rdma,60 = <&vioc_rdma VIOC_RDMA07>;
			telechips,disp = <&vioc_disp VIOC_DISP1>;
			telechips,sc = <&vioc_scaler VIOC_SCALER1>;
			viqe_rdma_num_60 = <VIOC_VIQE_RDMA_07>;
			sc_rdma_num_60 = <VIOC_SC_RDMA_07>;
		};

		tcc_video_viqe_external {
			telechips,wmixer = <&vioc_wmix VIOC_WMIX0>;
			telechips,rdma,60 = <&vioc_rdma VIOC_RDMA03>;
			telechips,disp = <&vioc_disp VIOC_DISP0>;
			telechips,sc = <&vioc_scaler VIOC_SCALER1>;
			viqe_rdma_num_60 = <VIOC_VIQE_RDMA_03>;
			sc_rdma_num_60 = <VIOC_SC_RDMA_03>;
		};

		tcc_video_viqe_external_sub {
			telechips,wmixer = <&vioc_wmix VIOC_WMIX0>;
			telechips,rdma,60 = <&vioc_rdma VIOC_RDMA02>;
			telechips,disp = <&vioc_disp VIOC_DISP0>;
			telechips,sc = <&vioc_scaler VIOC_SCALER3>;
			viqe_rdma_num_60 = <VIOC_VIQE_RDMA_02>;
			sc_rdma_num_60 = <VIOC_SC_RDMA_02>;
		};

		tcc_video_main_m2m{
			main_rdma_num_m2m = <VIOC_VIQE_RDMA_16>;
			telechips,main_rdma,m2m = <&vioc_rdma VIOC_RDMA16>;
		};

		tcc_video_sub_m2m {
			sub_rdma_num_m2m = <VIOC_VIQE_RDMA_07>;
			telechips,sub_rdma,m2m = <&vioc_rdma VIOC_RDMA07>;
		};

		tcc_video_scaler_main_m2m {
			clocks = <&clk_ddi DDIBUS_VIOC>;
			m2m_sc_rdma = <&vioc_rdma VIOC_RDMA16>;
			m2m_sc_scaler = <&vioc_scaler VIOC_SCALER1>; /* id:1, path:17 */
			m2m_sc_wmix = <&vioc_wmix VIOC_WMIX5>; /* id:5, path:6 */
			m2m_sc_wdma = <&vioc_wdma VIOC_WDMA06>;
			m2m_sc_scaler_path = <VIOC_SC_RDMA_16>;
			m2m_sc_settop_support = <1>;
		};

		tcc_video_scaler_sub_m2m {
			clocks = <&clk_ddi DDIBUS_VIOC>;
			m2m_sc_rdma = <&vioc_rdma VIOC_RDMA07>;
			m2m_sc_scaler = <&vioc_scaler VIOC_SCALER3>; /* id:3, path:7 */
			m2m_sc_wmix = <&vioc_wmix VIOC_WMIX1>; /* id:1, path:3 */
			m2m_sc_wdma = <&vioc_wdma VIOC_WDMA01>;
			m2m_sc_scaler_path = <VIOC_SC_RDMA_07>;
			m2m_sc_settop_support = <1>;
		};
	};

	vout_drv0: vout_drv@0 {
		compatible = "telechips,v4l2_vout";
		reg = <0x0 0x0>;					/* Dummy regs. */
		clocks = <&clk_ddi DDIBUS_VIOC>;

		rdma = <&vioc_rdma VIOC_RDMA03>;
		wmix = <&vioc_wmix VIOC_WMIX0>;
		disp = <&vioc_disp VIOC_DISP0>;

		subplane_rdma = <&vioc_rdma VIOC_RDMA02>;
		m2m_subplane_rdma = <&vioc_rdma VIOC_RDMA05>;
		m2m_rdma = <&vioc_rdma VIOC_RDMA07>;
		m2m_wmix = <&vioc_wmix VIOC_WMIX1>;
		m2m_wdma = <&vioc_wdma VIOC_WDMA01>;

		deintl_block = <&vioc_viqe VIOC_VIQE0>;
		scaler = <&vioc_scaler VIOC_SCALER1>;

		status = "disabled";
	};

	vout_drv1: vout_drv@1 {
		compatible = "telechips,v4l2_vout";
		reg = <0x1 0x0>;					/* Dummy regs. */
		clocks = <&clk_ddi DDIBUS_VIOC>;

		rdma = <&vioc_rdma VIOC_RDMA07>;
		wmix = <&vioc_wmix VIOC_WMIX1>;
		disp = <&vioc_disp VIOC_DISP1>;

		subplane_rdma = <&vioc_rdma VIOC_RDMA05>;
		m2m_subplane_rdma = <&vioc_rdma VIOC_RDMA13>;
		m2m_rdma = <&vioc_rdma VIOC_RDMA12>;
		m2m_wmix = <&vioc_wmix VIOC_WMIX3>;
		m2m_wdma = <&vioc_wdma VIOC_WDMA03>;

		deintl_block = <&vioc_deintls VIOC_DEINTLS0>;
		scaler = <&vioc_scaler VIOC_SCALER3>;

		status = "disabled";
	};

	tcc_tve: tve@72200000 {
		status = "disabled";
		compatible = "telechips,tcc-tve";
		reg = <0x72200000 0x100 0x72200800 0x10>;
		clocks = <&clk_ddi DDIBUS_NTSCPAL &clk_isoip_top ISOIP_TOP_VDAC_1CH>;
	};

	composite {
		status = "disabled";
		compatible = "telechips,tcc-composite";
		clocks = <&clk_peri PERI_LCD0 &clk_peri PERI_LCD1>;
		vioc-frequency = <27000000>;
		scaler = <&vioc_scaler VIOC_SCALER1>;
		config = <&vioc_config>;
		ddicfg = <&ddi_config>;
	};

	component {
		status = "disabled";
		compatible = "telechips,tcc-component";
		clocks = <&clk_peri PERI_LCD0 &clk_peri PERI_LCD1>;
		vioc-frequency = <74250000>;
		scaler = <&vioc_scaler VIOC_SCALER1>;
		config = <&vioc_config>;
		ddicfg = <&ddi_config>;
		pinctrl-names = "default", "idle";
		pinctrl-0 = <&lcd_lpxclk &lcd_lhsync &lcd_lvsync &lcd_lacbias &lcd_lpd >;
		pinctrl-1 = <&lcd_lpxclk_idle &lcd_lhsync_idle &lcd_lvsync_idle &lcd_lacbias_idle &lcd_lpd_idle>;
	};

	output_starter {
		status = "disabled";
		compatible = "telechips,tcc-output-starter";
		scaler = <&vioc_scaler VIOC_SCALER2>;
		ddicfg = <&ddi_config>;
		tve = <&tcc_tve>;

		hdmi_starter {
			label = "hdmi output starter";
			clocks = <&clk_peri PERI_LCD0>, <&clk_peri PERI_LCD1>, <&clk_peri PERI_HDMI>, <&clk_ddi DDIBUS_HDMI>, <&clk_isoip_top ISOIP_TOP_HDMI>;
			clock-names = "lcdc0-clk", "lcdc1-clk", "hdmi-pclk", "hdmi-hclk", "hdmi-phy";
			lcdc-clock-frequency = <27>;
			hdmi-clock-frequency = <24000000>;
		};

		composite_starter {
			label = "composite output starter";
			clocks = <&clk_peri PERI_LCD0>, <&clk_peri PERI_LCD1>;
			clock-names = "lcdc0-clk", "lcdc1-clk";
			lcdc-clock-frequency = <27000000>;
		};

		component_starter {
			label = "component output starter";
			clocks = <&clk_peri PERI_LCD0>, <&clk_peri PERI_LCD1>;
			clock-names = "lcdc0-clk", "lcdc1-clk";
			lcdc-clock-frequency = <74250000>;
		};
	};

	jpeg_enc {
		compatible = "telechips-jpegenc";
		status ="okay";
		clocks = <&clk_fbus FBUS_VBUS &clk_vpu VIDEOBUS_JENC>;
		jpu_base_addr = <0x75300000>;
	};

	/*
	 * Video Bus Block
	 */

	vpu_dev_mgr {
		compatible = "telechips,vpu_dev_mgr";
		reg = <0x75000000 0x4000>;
		interrupts = <GIC_SPI 23 IRQ_TYPE_LEVEL_HIGH>;
		clocks = <&clk_fbus FBUS_VBUS &clk_fbus FBUS_CODA &clk_vpu VIDEOBUS_COD &clk_vpu VIDEOBUS_JENC>; /* 0x106 vbus/clkctrl, 0x107: coda/clkctrl, 0xc2: vcoda/vpu-bus, 0xc0: jpu/vpu-bus*/
	};

	hevc_dev_mgr {
		compatible = "telechips,hevc_dev_mgr";
		reg = <0x75080000 0xA000>;
		interrupts = <GIC_SPI 21 IRQ_TYPE_LEVEL_HIGH>;
		clocks = <&clk_fbus FBUS_VBUS &clk_fbus FBUS_HEVC_VCE &clk_fbus FBUS_HEVC_VCPU &clk_fbus FBUS_HEVC_BPU &clk_vpu VIDEOBUS_HEVC>; /* 0x106 vbus/clkctrl, 0x10c: hevc_c/clkctrl, 0x10d: hevc_v/clkctrl, 0x10e: hevc_b/clkctrl, 0xc4: hevc/vpu-bus*/
	};

	jpu_dev_mgr {
		compatible = "telechips,jpu_dev_mgr";
		reg = <0x75180000 0x1000>;
		interrupts = <GIC_SPI 15 IRQ_TYPE_LEVEL_HIGH>;
		clocks = <&clk_fbus FBUS_VBUS &clk_vpu VIDEOBUS_JENC>; /* 0x106: vbus/clkctrl , 0x0c0: jpu/vpu-bus*/
	};

	tcc_switchmanager: tcc_switchmanager {
		compatible = "telechips,tcc_switchmanager";
		status = "disabled";
	};

	cm_bus: cm_bus {
		reg = <0x79080000 0x10000>,
		      <0x790A0000 0x80>,
		      <0x790B0000 0x80>,
		      <0x790F0000 0x50>;
		interrupts = <GIC_SPI 31 IRQ_TYPE_LEVEL_LOW>;
		clocks = <&clk_fbus FBUS_CMBUS>,
		         <&clk_peri PERI_CMBUS_TSIF0>,
		         <&clk_peri PERI_CMBUS_TSIF1>,
		         <&clk_peri PERI_CMBUS_TSIF2>,
		         <&clk_peri PERI_CMBUS_TSIF3>;
		clock-frequency = <200000000>;
		status = "disabled";
	};

	tcc_cm_ctrl {
		compatible = "telechips,tcc_cm_ctrl";
		reg = <0x790A0000 0x10000
		       0x790B0000 0x10000
		       0x79080000 0x10000
		       0x79090000 0x10000
		       0x790F0000 0x10000>;
		reg-names = "mbox_0", "mbox_1", "code_mem", "data_mem", "config";
		clocks = <&clk_fbus FBUS_CMBUS>;
		tcc_cm_bus = <&cm_bus>;
		status = "okay";
	};

	videoinput0: videoinput@0 {
		compatible	= "telechips,video-input";
		clocks		= <&clk_ddi DDIBUS_VIOC>;
		cifport		= <&cifport		4>;
		rdma		= <&vioc_rdma		VIOC_RDMA15>;
		vin		= <&vioc_vin		VIOC_VIN30>;
		viqe		= <&vioc_viqe		VIOC_VIQE>;
		viqe_set	= <&viqe_hidden>;
		deintls		= <&vioc_deintls	VIOC_DEINTLS>;
		scaler		= <&vioc_scaler		VIOC_SCALER0>;
		wmixer		= <&vioc_wmix		VIOC_WMIX4>;
		wdma		= <&vioc_wdma		VIOC_WDMA04>;
		fifo		= <&vioc_fifo		VIOC_FIFO0>;
		status		= "okay";
	};

	/*
	 * Misc. Devices
	 */
	scaler_drv_common: scaler_drv_common@1 {
		compatible = "telechips,scaler_drv_common";
		reg = <0x1 0x0>;
		clocks = <&clk_ddi DDIBUS_VIOC>;
		interrupts = <GIC_SPI 20 IRQ_TYPE_LEVEL_HIGH>;
		status = "disabled";
	};

	scaler_drv1: scaler_drv@1 {
		compatible = "telechips,scaler_drv";
		reg = <0x1 0x0>;
		clocks = <&clk_ddi DDIBUS_VIOC>;
		rdmas = <&vioc_rdma VIOC_RDMA16>;
		scalers = <&vioc_scaler VIOC_SCALER1>;
		wmixs = <&vioc_wmix VIOC_WMIX5>;	/* id:5, path:6 */
		wdmas = <&vioc_wdma VIOC_WDMA06>;
		settop_support = <0>;
		status = "okay";
	};

	scaler_drv3: scaler_drv@3 {
		compatible = "telechips,scaler_drv";
		reg = <0x3 0x0>;
		clocks = <&clk_ddi DDIBUS_VIOC>;
		rdmas = <&vioc_rdma VIOC_RDMA07>;
		scalers = <&vioc_scaler VIOC_SCALER3>;
		wmixs = <&vioc_wmix VIOC_WMIX1>;	/* id:1, path:2 */
		wdmas = <&vioc_wdma VIOC_WDMA01>;
		settop_support = <0>;
		status = "okay";
	};

	wmixer_drv0: wmixer_drv@0 {
		compatible = "telechips,wmixer_drv";
		reg = <0x0 0x0>;	/* Dummy regs. */
		clocks = <&clk_ddi DDIBUS_VIOC>;
		rdmas = <&vioc_rdma VIOC_RDMA15>;
		scalers = <&vioc_scaler VIOC_SCALER0>;	/* id:0, path:15 */
		wmixs = <&vioc_wmix VIOC_WMIX4>;	/* id:5, path:- TODO: WMIX_MAX occurs error*/
		wdmas = <&vioc_wdma VIOC_WDMA04>;
		status = "okay";
	};

	wmixer_drv1: wmixer_drv@1 {
		compatible = "telechips,wmixer_drv";
		reg = <0x1 0x0>;	/* Dummy regs. */
		clocks = <&clk_ddi DDIBUS_VIOC>;
		rdmas = <&vioc_rdma VIOC_RDMA13>;
		wmixs = <&vioc_wmix VIOC_WMIX3>;	/* id:3, path:- TODO: WMIX_MAX occurs error*/
		wdmas = <&vioc_wdma VIOC_WDMA03>;
		status = "okay";
	};

	wdma_drv0:wdma_drv@0 {
		compatible = "telechips,tcc_wdma";
		//clocks = <&clk_fbus FBUS_DDI>;
		clocks = <&clk_ddi DDIBUS_VIOC>;
		wdma-fbdisplay = <&fbdisplay>;
		scalers = <&vioc_scaler VIOC_SCALER0>, <&vioc_scaler VIOC_SCALER0>;       /* id:1, path:20 (wdma 0 path), 21(wdma 1 path) */
		wdmas = <&vioc_wdma VIOC_WDMA00>, <&vioc_wdma VIOC_WDMA01>;   /* id:1, path: wmix output mixed pah */
		wmixs = <&vioc_wmix VIOC_WMIX0>, <&vioc_wmix VIOC_WMIX1>;      /* id:1, path: input rdma mixed path */
		status = "okay";
	};

	tcc_dsp: tcc_dsp@0 {
		compatible = "telechips,tcc_dsp";
		status = "disable";
	};

	tcc_nsk_sc: tcc_nsk_sc@763E0000 {
		compatible = "telechips,tcc-nsk-sc";
		reg = <0x763E0000 0xFF>,
		      <0x763F0000 0x1F>,
		      <0x76066000 0x70>,
		      <0x76040100 0x2F>;
		interrupts = <GIC_SPI 47 IRQ_TYPE_LEVEL_HIGH>;
		clocks = <&clk_peri PERI_UART7>, <&clk_io IOBUS_UART7>;
		clock-names = "uartclk", "apb_pclk";
		clock-frequency = <54857142>;

		iobus_dmareqsel_offset = <0x60>;
		iobus_dmareqsel_value = <0x800>;
		iobus_hrsten_offset = <0x6C>;
		iobus_hrsten_value = <0x2>;

		dma_extreq_value = <0x800>;

		uart_chnum = <7>;
		uart_port = <23>;
		uart_datmux_use = <0>;
	};

	tcc_smartcard{
		compatible = "telechips,tcc-smartcard";
		reg = <0x763B0000 0x80 0x763F0000 0x10>;		//UART4_BASE, UART_PORT_CFG

		clock-frequency = <54000000>;

		uart_ch = <&uart4>;
		uart_chnum = <4>;
		uart_port = <23>;
		detect_timer_used = <0>;
		detect_check = <1>;
		gpio_fun = <9>;
		tda8024_used = <1>;

		rst_gpios = <&gpc 28 0>;
		detect_gpios = <&gpc 9 0>;
		pwren_gpios = <&gpc 20 0>;
		clk_gpios = <&gpf 27 0>;
		data_c7_gpios =<&gpf 26 0>;
		status = "okay";
	};

	firmware {
		optee {
			compatible = "linaro,optee-tz";
			method = "none";
		};
	};
};
